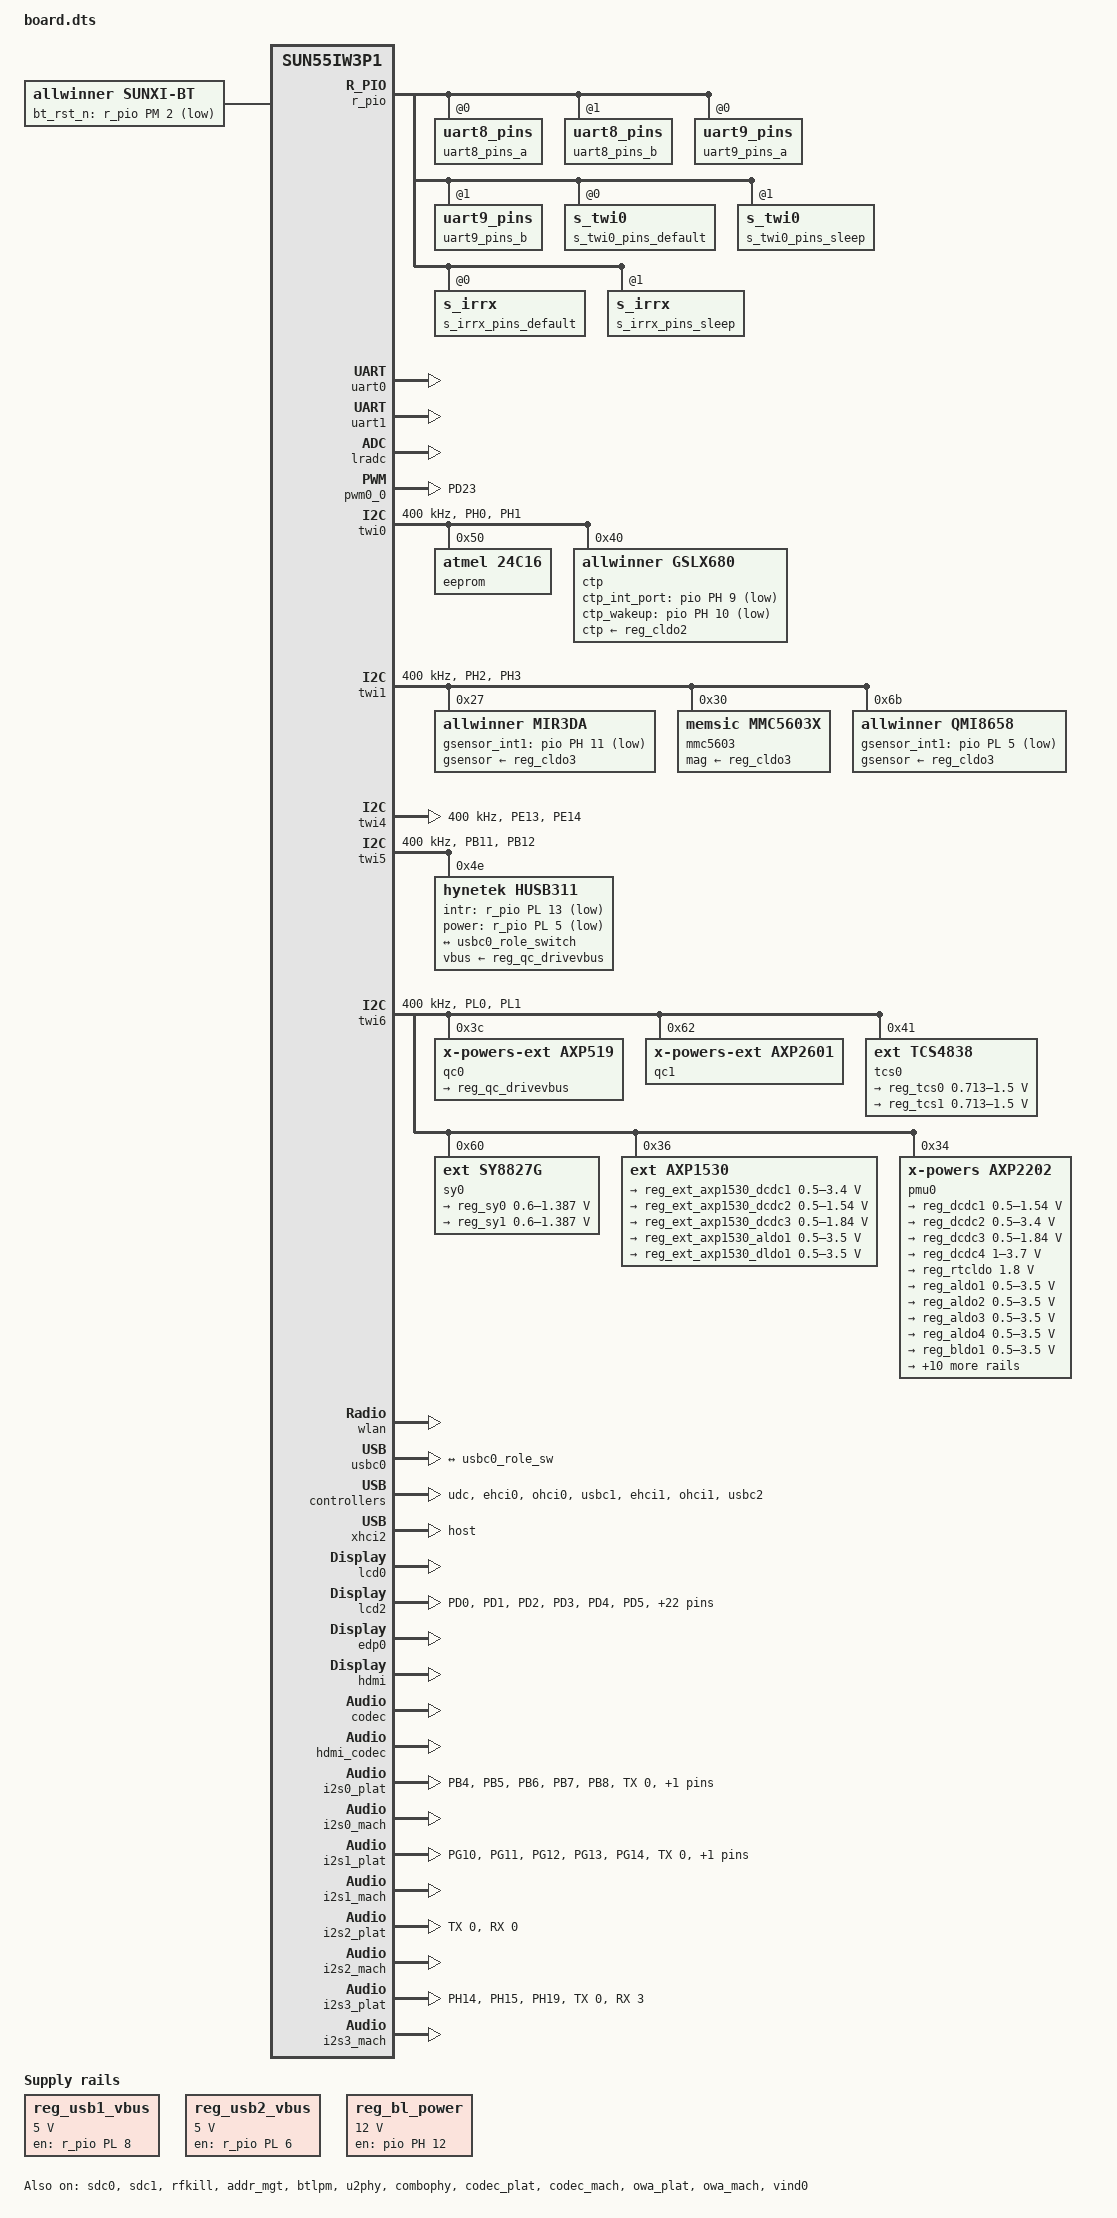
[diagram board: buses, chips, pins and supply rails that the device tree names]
/*
 * Allwinner Technology CO., Ltd.
 */

/dts-v1/;

#include "sun55iw3p1.dtsi"

/{
	board = "A527", "A527-PRO2-AXP717C";
	compatible = "allwinner,a523", "arm,sun55iw3p1";
	aliases {
		pmu0 = &pmu0;
		axp1530 = &axp1530;
		serial0 = &uart0;
		lcd0 = &lcd0;
		hdmi = &hdmi;
		reg-tcs0 = &reg_tcs0;
		reg-sy0 = &reg_sy0;
		reg-axp1530 = &reg_ext_axp1530_dcdc1;
		tcs0 = &tcs0;
		sy0 = &sy0;
		cpu-ext = &cpu4;
		standby-param = &standby_param;
		arisc-config = &arisc_config;
	};

	reg_usb1_vbus: usb1-vbus {
		compatible = "regulator-fixed";
		regulator-name = "usb1-vbus";
		regulator-min-microvolt = <5000000>;
		regulator-max-microvolt = <5000000>;
		regulator-enable-ramp-delay = <1000>;
		gpio = <&r_pio PL 8 GPIO_ACTIVE_HIGH>;
		enable-active-high;
	};

	reg_usb2_vbus: usb2-vbus {
		compatible = "regulator-fixed";
		regulator-name = "usb2-vbus";
		regulator-min-microvolt = <5000000>;
		regulator-max-microvolt = <5000000>;
		regulator-enable-ramp-delay = <1000>;
		gpio = <&r_pio PL 6 GPIO_ACTIVE_HIGH>;
		enable-active-high;
	};

	reg_bl_power: backlight-power {
		compatible = "regulator-fixed";
		regulator-name = "backlight-power";
		regulator-min-microvolt = <12000000>;
		regulator-max-microvolt = <12000000>;
		regulator-enable-ramp-delay = <1000>;
		regulator-boot-on;
		gpio = <&pio PH 12 GPIO_ACTIVE_HIGH>;
		enable-active-high;
	};


	standby_param: standby_param {
		vdd-cpu = <0x00000001>;
		vdd-cpub = <0x00000001>;
		vdd-ndr = <0x00000004>;
		vdd-sys = <0x00000002>;
		vcc-pll = <0x00000080>;
		vcc-io  = <0x00004000>;

		osc24m-on = <0x0>;
	};

	arisc_config: arisc_config {
		s_uart_config{
			pins = "PL2", "PL3";
			function = <2>, <2>;
			status = "disabled";
		};
	};
};

&r_pio {
	uart8_pins_a: uart8_pins@0 {
		pins = "PL2", "PL3";
		function = "s_uart0";
	};

	uart8_pins_b: uart8_pins@1 {
		pins = "PL2", "PL3";
		function = "gpio_in";
	};

	uart9_pins_a: uart9_pins@0 {
		pins = "PM0", "PM1";
		function = "s_uart1";
	};

	uart9_pins_b: uart9_pins@1 {
		pins = "PM0", "PM1";
		function = "gpio_in";
	};

	s_twi0_pins_default: s_twi0@0 {
		pins = "PL0", "PL1";
		function = "s_twi0";
		drive-strength = <10>;
		bias-pull-up;
	};

	s_twi0_pins_sleep: s_twi0@1 {
		pins = "PL0", "PL1";
		function = "gpio_in";
	};

	s_irrx_pins_default: s_irrx@0 {
		pins = "PL11";
		function = "s_cir";
	};

	s_irrx_pins_sleep: s_irrx@1 {
	        pins = "PL11";
		function = "gpio_in";
	};
};

&pio {
	vcc-pg-supply = <&reg_pio1_8>;
	vcc-pc-supply = <&reg_pio1_8>;
	vcc-pf-supply = <&reg_pio1_8>;
	vcc-pfo-supply = <&reg_pio3_3>;

	uart0_pins_a: uart0_pins@0 {
		pins = "", "";
		function = "uart0";
	};

	uart0_pins_b: uart0_pins@1 {
		pins = "", "";
		function = "gpio_in";
	};

	uart2_pins_a: uart2_pins@0 {
		pins = "PB0", "PB1";
		function = "uart2";
	};

	uart2_pins_b: uart2_pins@1 {
		pins = "PB0", "PB1";
		function = "gpio_in";
	};

	uart3_pins_a: uart3_pins@0 {
		pins = "PD14", "PD15";
		function = "uart3";
	};

	uart3_pins_b: uart3_pins@1 {
		pins = "PD14", "PD15";
		function = "gpio_in";
	};

	uart4_pins_a: uart4_pins@0 {
		pins = "PD18", "PD19";
		function = "uart4";
	};

	uart4_pins_b: uart4_pins@1 {
		pins = "PD18", "PD19";
		function = "gpio_in";
	};

	uart5_pins_a: uart5_pins@0 {
		pins = "PE11", "PE12";
		function = "uart5";
	};

	uart5_pins_b: uart5_pins@1 {
		pins = "PE11", "PE12";
		function = "gpio_in";
	};

	uart6_pins_a: uart6_pins@0 {
		pins = "PK18", "PK19";
		function = "uart6";
	};

	uart6_pins_b: uart6_pins@1 {
		pins = "PK18", "PK19";
		function = "gpio_in";
	};

	uart7_pins_a: uart7_pins@0 {
		pins = "PB11", "PB12";
		function = "uart7";
	};

	uart7_pins_b: uart7_pins@1 {
		pins = "PB11", "PB12";
		function = "gpio_in";
	};

	pwm0_0_pin_active: pwm0_0@0 {
		pins = "PD23";
		function = "pwm0_0";
		drive-strength = <10>;
	};

	pwm0_0_pin_sleep: pwm0_0@1 {
		pins = "PD23";
		function = "gpio_in";
	};

	ledc_pins_a: ledc@0 {
		pins = "PE5";
		function = "ledc";
		drive-strength = <10>;
	};

	ledc_pins_b: ledc@1 {
		pins = "PE5";
		function = "gpio_in";
	};

	irrx_pins_default: irrx@0 {
		pins = "PH19";
		function = "cir";
	};

	irrx_pins_sleep: irrx@1 {
	        pins = "PH19";
	        function = "gpio_in";
	};

	irtx_pins_default: irtx@0 {
		pins = "PH18";
		function = "cir";
	};

	irtx_pins_sleep: irtx@1 {
		pins = "PH18";
		function = "gpio_in";
	};

	twi0_pins_default: twi0@0 {
		pins = "PH0", "PH1";
		function = "twi0";
		drive-strength = <10>;
		bias-pull-up;
	};

	twi0_pins_sleep: twi0@1 {
		pins = "PH0", "PH1";
		function = "gpio_in";
	};

	twi1_pins_default: twi1@0 {
		pins = "PH2", "PH3";
		function = "twi1";
		drive-strength = <10>;
		bias-pull-up;
	};

	twi1_pins_sleep: twi1@1 {
		pins = "PH2", "PH3";
		function = "gpio_in";
	};

	twi4_pins_default: twi4@0 {
		pins = "PE13", "PE14";
		function = "twi4";
		drive-strength = <20>;
		bias-pull-up;
	};

	twi4_pins_sleep: twi4@1 {
		pins = "PE13", "PE14";
		function = "gpio_in";
	};

	twi5_pins_default: twi5@0 {
		pins = "PB11", "PB12";
		function = "twi5";
		drive-strength = <30>;
		bias-pull-up;
	};

	twi5_pins_sleep: twi5@1 {
		pins = "PB11", "PB12";
		function = "gpio_in";
	};

	rgb24_pins_a: rgb24@0 {
		pins = "PD0", "PD1", "PD2", "PD3", "PD4", "PD5", "PD6", "PD7", "PD8", "PD9", \
			"PD10", "PD11", "PD12", "PD13", "PD14", "PD15", "PD16", "PD17", "PD18", "PD19", \
			"PD20", "PD21", "PD22","PD23","PD24","PD25","PD26","PD27";
		      function = "dpss";
		      drive-strength = <30>;
	      };
	rgb24_pins_b: rgb24@1 {
		pins = "PD0", "PD1", "PD2", "PD3", "PD4", "PD5", "PD6", "PD7", "PD8", "PD9", \
			"PD10", "PD11", "PD12", "PD13", "PD14", "PD15", "PD16", "PD17", "PD18", "PD19", \
			"PD20", "PD21", "PD22", "PD23","PD24","PD25","PD26","PD27";
		      function = "gpio_in";
	      };
	lvds0_pins_a: lvds0@0 {
		pins = "PD0", "PD1", "PD2", "PD3", "PD4", "PD5", "PD6", "PD7", "PD8", "PD9";
		      function = "lvds";
		      drive-strength = <30>;
	      };
	lvds0_pins_b: lvds0@1 {
		      pins = "PD0", "PD1", "PD2", "PD3", "PD4", "PD5", "PD6", "PD7", "PD8", "PD9";
		      function = "gpio_in";
	      };

	csi_mclk3_pins_a: csi_mclk3@0 {
		pins = "PE10";
		function = "mipi3";
		drive-strength = <20>;
	};

	csi_mclk3_pins_b: csi_mclk3@1 {
		pins = "PE10";
		function = "gpio_in";
	};

	ncsi_pins_a: ncsi@0 {
		pins = "PK12", "PK14", "PK15",
		"PK16", "PK17", "PK18", "PK19",
		"PK20", "PK21", "PK22", "PK23",
		"PE6", "PE7", "PE8", "PE9",
		"PE10", "PE11", "PE12", "PE15";
		function = "ncsi";
		drive-strength = <20>;
	};

	ncsi_pins_b: ncsi@1 {
		pins = "PK12", "PK14", "PK15",
		"PK16", "PK17", "PK18", "PK19",
		"PK20", "PK21", "PK22", "PK23",
		"PE6", "PE7", "PE8", "PE9",
		"PE10", "PE11", "PE12", "PE15";
		function = "gpio_in";
	};

	i2s1_pins_a: i2s1@0 {
		pins = "PG10", "PG11", "PG12";
		function = "i2s1";
		drive-strength = <20>;
		bias-disable;
	};

	i2s1_pins_b: i2s1@1 {
		pins = "PG10", "PG11", "PG12", "PG13", "PG14";
		function = "io_disabled";
		drive-strength = <20>;
		bias-disable;
	};

	i2s1_pins_c: i2s1@2 {
		pins = "PG13";
		function = "i2s1_dout";
		drive-strength = <20>;
		bias-disable;
	};

	i2s1_pins_d: i2s1@3 {
		pins = "PG14";
		function = "i2s1_din";
		drive-strength = <20>;
		bias-disable;
	};

	i2s3_pins_a: i2s3@0 {
		pins = "PH14", "PH15";
		function = "i2s3";
		drive-strength = <20>;
		bias-disable;
	};

	i2s3_pins_b: i2s3@1 {
		pins = "PH14", "PH15", "PH19";
		function = "io_disabled";
		drive-strength = <20>;
		bias-disable;
	};

	i2s3_pins_c: i2s3@2 {
		pins = "PH19";
		function = "i2s3_din";
		drive-strength = <20>;
		bias-disable;
	};

	owa_pins_a: owa@0 {
		pins = "PH7";
		function = "owa";
		drive-strength = <20>;
		bias-disable;
	};

	owa_pins_b: owa@1 {
		pins = "PH7";
		function = "io_disabled";
		drive-strength = <20>;
		bias-disable;
	};

	nand0_pins_default: nand0@0 {
		pins = "PC0", "PC1", "PC2", "PC5",
			 "PC8", "PC9", "PC10", "PC11",
			 "PC12", "PC13", "PC14", "PC15",
			 "PC16";
		function = "nand0";
		drive-strength = <30>;
	};

	nand0_pins_rb: nand0@1 {
		pins = "PC4", "PC6", "PC3", "PC7";
		function = "nand0";
		drive-strength = <30>;
		bias-pull-up;   /* only RB&CE should be pulled up */
	};

	nand0_pins_sleep: nand0@2 {
		pins = "PC0", "PC1", "PC2", "PC3",
			 "PC4", "PC5", "PC6", "PC7",
			 "PC8", "PC9", "PC10", "PC11",
			 "PC12", "PC13", "PC14", "PC15",
			 "PC16";
		function = "io_disabled";
		drive-strength = <10>;
	};

	i2s0_pins_a: i2s0@0 {
		pins = "PB4", "PB5", "PB6";
		function = "i2s0";
		drive-strength = <20>;
		bias-disable;
	};

	i2s0_pins_b: i2s0@1 {
		pins = "PB4", "PB5", "PB6", "PB7", "PB8";
		function = "io_disabled";
		drive-strength = <20>;
		bias-disable;
	};

	i2s0_pins_c: i2s0@2 {
		pins = "PB7";
		function = "i2s0_dout";
		drive-strength = <20>;
		bias-disable;
	};

	i2s0_pins_d: i2s0@3 {
		pins = "PB8";
		function = "i2s0_din";
		drive-strength = <20>;
		bias-disable;
	};
};

&soc {
	auto_print@54321 {
		reg = <0x0 0x54321 0x0 0x0>;
		device_type = "auto_print";
		status = "okay";
	};

	hall_para {
		hall_name = "MH248";
		status = "okay";
		hall_int_port = <&r_pio PL 9 GPIO_ACTIVE_LOW>;
	};

};

&uart0 {
	pinctrl-names = "default", "sleep";
	pinctrl-0 = <&uart0_pins_a>;
	pinctrl-1 = <&uart0_pins_b>;
	uart-supply = <&reg_cldo3>;
	status = "okay";
};

&uart1 {
	status = "okay";
};

&uart2 {
	pinctrl-names = "default", "sleep";
	pinctrl-0 = <&uart2_pins_a>;
	pinctrl-1 = <&uart2_pins_b>;
	status = "disabled";
};

&uart3 {
	pinctrl-names = "default", "sleep";
	pinctrl-0 = <&uart3_pins_a>;
	pinctrl-1 = <&uart3_pins_b>;
	status = "disabled";
};

&uart4 {
	pinctrl-names = "default", "sleep";
	pinctrl-0 = <&uart4_pins_a>;
	pinctrl-1 = <&uart4_pins_b>;
	status = "disabled";
};

&uart5 {
	pinctrl-names = "default", "sleep";
	pinctrl-0 = <&uart5_pins_a>;
	pinctrl-1 = <&uart5_pins_b>;
	status = "disabled";
};

&uart6 {
	pinctrl-names = "default", "sleep";
	pinctrl-0 = <&uart6_pins_a>;
	pinctrl-1 = <&uart6_pins_b>;
	status = "disabled";
};

&uart7 {
	pinctrl-names = "default", "sleep";
	pinctrl-0 = <&uart7_pins_a>;
	pinctrl-1 = <&uart7_pins_b>;
	status = "disabled";
};

&uart8 {
	pinctrl-names = "default", "sleep";
	pinctrl-0 = <&uart8_pins_a>;
	pinctrl-1 = <&uart8_pins_b>;
	status = "disabled";
};

&uart9 {
	pinctrl-names = "default", "sleep";
	pinctrl-0 = <&uart9_pins_a>;
	pinctrl-1 = <&uart9_pins_b>;
	status = "disabled";
};

&lradc {
	key_cnt = <2>;
	key0 = <646 115>;
	key1 = <900 114>;
	status = "okay";
};

&gpadc0 {
	channel_num = <2>;
	channel_select = <3>;
	channel_data_select = <3>;
	channel_compare_select = <3>;
	channel_cld_select = <3>;
	channel_chd_select = <3>;
	channel0_compare_lowdata = <1700000>;
	channel0_compare_higdata = <1200000>;
	channel1_compare_lowdata = <460000>;
	channel1_compare_higdata = <1200000>;
	status = "disabled";
};

&gpadc1 {
	channel_num = <2>;
	channel_select = <3>;
	channel_data_select = <3>;
	channel_compare_select = <3>;
	channel_cld_select = <3>;
	channel_chd_select = <3>;
	channel0_compare_lowdata = <1700000>;
	channel0_compare_higdata = <1200000>;
	channel1_compare_lowdata = <460000>;
	channel1_compare_higdata = <1200000>;
	status = "disabled";
};

&pwm0_0 {
	pinctrl-names = "active", "sleep";
	pinctrl-0 = <&pwm0_0_pin_active>;
	pinctrl-1 = <&pwm0_0_pin_sleep>;
	status = "okay";
};

&ledc  {
	pinctrl-names = "default", "sleep";
	pinctrl-0 = <&ledc_pins_a>;
	pinctrl-1 = <&ledc_pins_b>;
	led_count = <34>;
	output_mode = "GRB";
	reset_ns = <84>;
	t1h_ns = <800>;
	t1l_ns = <320>;
	t0h_ns = <300>;
	t0l_ns = <800>;
	wait_time0_ns = <84>;
	wait_time1_ns = <84>;
	wait_data_time_ns = <600000>;
	status = "disabled";
};

&irrx {
	pinctrl-names = "default", "sleep";
	pinctrl-0 = <&irrx_pins_default>;
	pinctrl-1 = <&irrx_pins_sleep>;
	status = "disabled";
};

&s_irrx {
	pinctrl-names = "default", "sleep";
	pinctrl-0 = <&s_irrx_pins_default>;
	pinctrl-1 = <&s_irrx_pins_sleep>;
	status = "disabled";
};

&irtx {
	pinctrl-names = "default", "sleep";
	pinctrl-0 = <&irtx_pins_default>;
	pinctrl-1 = <&irtx_pins_sleep>;
	status = "disabled";
};

&twi0 {
	clock-frequency = <400000>;
	pinctrl-0 = <&twi0_pins_default>;
	pinctrl-1 = <&twi0_pins_sleep>;
	pinctrl-names = "default", "sleep";
	/* For stability and backwards compatibility, we recommend setting ‘twi_drv_used’ to 1 */
	twi_drv_used = <1>;
	status = "okay";

	eeprom@50 {
		compatible = "atmel,24c16";
		reg = <0x50>;
		status = "okay";
	};
	pcie_usb_phy@74 {
		compatible = "combphy,phy74";
		reg = <0x74>;
		status = "disabled";
	};
	pcie_usb_phy@75 {
		compatible = "combphy,phy75";
		reg = <0x75>;
		status = "disabled";
	};

	ctp: ctp@0 {
		compatible = "allwinner,gslX680";
		reg = <0x40>;
		device_type = "ctp";
		status = "okay";
		ctp_name = "gslX680_5680_d10";
		ctp_twi_id = <0x0>;
		ctp_twi_addr = <0x40>;
		ctp_screen_max_x = <0x780>;
		ctp_screen_max_y = <0x438>;
		ctp_revert_x_flag = <0x0>;
		ctp_revert_y_flag = <0x0>;
		ctp_exchange_x_y_flag = <0x1>;
		ctp_int_port = <&pio PH 9 GPIO_ACTIVE_LOW>;
		//ctp_power_io = <&pio PH 14 GPIO_ACTIVE_LOW>;
		ctp_wakeup = <&pio PH 10 GPIO_ACTIVE_LOW>;
		ctp-supply = <&reg_cldo2>;
		ctp_power_ldo_vol = <3300>;
	};
};

&twi1 {
	clock-frequency = <400000>;
	pinctrl-0 = <&twi1_pins_default>;
	pinctrl-1 = <&twi1_pins_sleep>;
	pinctrl-names = "default", "sleep";
	/* For stability and backwards compatibility, we recommend setting ‘twi_drv_used’ to 1 */
	twi_drv_used = <1>;
	status = "okay";
        /*DA215S  DA221*/
	mir3da {
		compatible = "allwinner,mir3da";
		reg = <0x27>;
		device_type = "gsensor";
		status = "okay";
		gsensor_twi_id = <0x1>;
		gsensor_twi_addr = <0x27>;
		gsensor_int1 = <&pio PH 11 (GPIO_ACTIVE_LOW | GPIO_PULL_UP)>;
		gsensor-supply = <&reg_cldo3>;
		gsensor_vcc_io_val = <3300>;
	};
	/*ms311*/
	msa {
		compatible = "allwinner,msa";
		reg = <0x62>;
		device_type = "gsensor";
		status = "disabled";
		gsensor_twi_id = <0x1>;
		gsensor_twi_addr = <0x62>;
		gsensor_int1 = <&pio PH 11 (GPIO_ACTIVE_LOW | GPIO_PULL_UP)>;
		gsensor-supply = <&reg_cldo3>;
		gsensor_vcc_io_val = <3300>;
	};
	mmc5603 {
		compatible = "memsic,mmc5603x";
		reg = <0x30>;
		status = "okay";
		device_type = "magnetormetersensor";
		mag_twi_id = <0x1>;
		mag_twi_addr = <0x26>;
		mag-supply = <&reg_cldo3>;
		mag_vcc_io_val = <3300>;
	};

	qmi8658 {
		compatible = "allwinner,qmi8658";
		reg = <0x6b>;
		device_type = "gsensor";
		status = "okay";
		gsensor_twi_id = <0x1>;
		gsensor_twi_addr = <0x6b>;
		gsensor_int1 = <&pio PL 5 (GPIO_ACTIVE_LOW | GPIO_PULL_UP)>;
		gsensor-supply = <&reg_cldo3>;
		gsensor_vcc_io_val = <3300>;
	};
};

&twi4 {
	clock-frequency = <400000>;
	pinctrl-0 = <&twi4_pins_default>;
	pinctrl-1 = <&twi4_pins_sleep>;
	pinctrl-names = "default", "sleep";
	/* For stability and backwards compatibility, we recommend setting ‘twi_drv_used’ to 1 */
	twi_drv_used = <1>;
	status = "okay";
};

&twi5 {
	clock-frequency = <400000>;
	pinctrl-0 = <&twi5_pins_default>;
	pinctrl-1 = <&twi5_pins_sleep>;
	pinctrl-names = "default", "sleep";
	/* For stability and backwards compatibility, we recommend setting ‘twi_drv_used’ to 1 */
	twi_drv_used = <1>;
	status = "okay";

	ac107: ac107@36 {
		#sound-dai-cells        = <0>;
		compatible              = "allwinner,sunxi-ac107";
		reg                     = <0x36>;
		pllclk-src              = "MCLK";
		sysclk-src              = "MCLK";
		pcm-bit-first           = "MSB";
		frame-sync-width        = <1>;
		rx-chmap                = <0xaaaa>;
		ch1-dig-vol             = <160>;
		ch2-dig-vol             = <160>;
		ch1-pga-gain            = <26>;
		ch2-pga-gain            = <26>;
		status                  = "disabled";
	};
	husb311: husb311@4e {
		compatible = "hynetek,husb311";
		reg = <0x4e>;
		interrupt-parent = <&r_pio>;
		husb311,intr_gpio = <&r_pio PL 13 GPIO_ACTIVE_LOW>;
		power_gpios = <&r_pio PL 5 GPIO_ACTIVE_LOW>;
		vbus-supply = <&reg_qc_drivevbus>;
		det_usb_supply = <&charger_power_supply>;
		aw,vbus-debounce-quirk;
		aw,vbus-tryon-debounce = <1200>;
		aw,vbus-check-debounce = <600>;
		/* aw,vbus-wakeup-quirk; */
		/* aw,port-reset-quirk; */
		aw,otg-detect-quirk;
		status = "okay";

		ports {
			#address-cells = <1>;
			#size-cells = <0>;

			port@0 {
				reg = <0>;
				usbc0_role_sw: endpoint@0 {
					remote-endpoint = <&usbc0_role_switch>;
				};
			};
		};

		usb_con: connector {
			compatible = "usb-c-connector";
			label = "USB-C";
			data-role = "dual";
			power-role = "dual";
			try-power-role = "sink";
			op-sink-microwatt = <1000000>;
			slow-charger-loop;
			//pd-disable;
			//typec-power-opmode = "default";
			sink-pdos = < PDO_FIXED(5000, 500, (0x1<<29)|(0x1<<25))
						 PDO_VAR(5000, 5000, 2000)
						 PDO_VAR(9000, 9000, 2000)
						 PDO_VAR(12000, 12000, 3000)
						 PDO_VAR(15000, 15000, 3000)
						 PDO_VAR(20000, 20000, 2250)
						>;
			source-pdos = < PDO_FIXED(5000, 500, (0x1<<29)|(0x1<<25))
							PDO_VAR(5000, 5000, 1200) >;
			/* fixme */
			sink-vdos = <0xd1002e99 0x00 0x03110000>;
			sink-vdos-v1 = <0xd1002e99 0x00 0x03110000>;

			altmodes {
				#address-cells = <1>;
				#size-cells = <0>;

				altmode@0 {
					reg = <0>;
					svid = <0xff01>;
					vdo = <0xffffffff>;
				};
			};

			ports {
				#address-cells = <1>;
				#size-cells = <0>;

/*
				port@0 {
					reg = <0>;
					usbc2_orien_sw: endpoint {
						remote-endpoint = <&usbdp_orientation_switch>;
					};
				};
				port@1 {
					reg = <1>;
					dp_altmode_mux: endpoint {
						remote-endpoint = <&usbdp_dp_altmode_mux>;
					};
				};
*/
			};
		};
	};
};
&twi6 {
	clock-frequency = <400000>;
	pinctrl-0 = <&s_twi0_pins_default>;
	pinctrl-1 = <&s_twi0_pins_sleep>;
	pinctrl-names = "default", "sleep";
	device_type = "twi6";
	/* For stability and backwards compatibility, we recommend setting ‘twi_drv_used’ to 1 */
	twi_drv_used = <1>;
	no_suspend = <1>;
	status = "okay";

	qc0: qc@3c{
		compatible = "x-powers-ext,axp519";
		reg = <0x3c>;
		status = "okay";
		interrupts = <0 IRQ_TYPE_LEVEL_LOW>;
		interrupt-parent = <&nmi_intc>;
		quick-charge,drive-vbus-en;
		wakeup-source;

		charger_power_supply: charger_power_supply{
			compatible = "x-powers-ext,axp519-charger-power-supply";
			status = "okay";
			wakeup-source;
			det_battery_supply = <&qc_bat_power_supply>;
			pmu_runtime_chgcur = <2000>;
			pmu_suspend_chgcur = <3000>;
			pmu_shutdown_chgcur = <3000>;
			pmu_chargerpc_vol = <5000>;
			pmu_chargerpc_cur = <500>;
			pmu_chargerad_vol = <5000>;
			pmu_chargerad_cur = <2400>;
			battery_exist_sets = <1>;
		};
		regulator4: regulators@4 {
			reg_qc_drivevbus: drivevbus {
				regulator-name = "axp519-drivevbus";
				regulator-enable-ramp-delay = <1000>;
			};
		};
	};

	qc1: qc@62{
		compatible = "x-powers-ext,axp2601";
		reg = <0x62>;
		status = "okay";
		interrupts = <0 IRQ_TYPE_LEVEL_LOW>;
		interrupt-parent = <&nmi_intc>;
		wakeup-source;

		qc_bat_power_supply: qc_bat_power_supply {
			compatible = "x-powers-ext,axp2601-bat-power-supply";
			param = <&axp2202_parameter>;
			status = "okay";
			wakeup-source;
			det_qc_supply = <&charger_power_supply>;
			pmu_init_chgvol = <8700>;

			pmu_bat_temp_enable = <1>;
			pmu_bat_charge_ltf = <27280>;//0
			pmu_bat_charge_htf = <3536>;//55
			pmu_bat_work_ltf = <27280>;//0
			pmu_bat_work_htf = <3536>;//55
			pmu_bat_shutdown_ltf = <42470>;//-10
			pmu_bat_shutdown_htf = <2588>;//65
			pmu_bat_temp_para1 = <86430>;//-25
			pmu_bat_temp_para2 = <53410>;//-15
			pmu_bat_temp_para3 = <42470>;//-10
			pmu_bat_temp_para4 = <33900>;//-5
			pmu_bat_temp_para5 = <27280>;//0
			pmu_bat_temp_para6 = <22050>;//5
			pmu_bat_temp_para7 = <17960>;//10
			pmu_bat_temp_para8 = <14690>;//15
			pmu_bat_temp_para9 = <12090>;//20
			pmu_bat_temp_para10 = <10000>;//25
			pmu_bat_temp_para11 = <8313>;//30
			pmu_bat_temp_para12 = <5827>;//40
			pmu_bat_temp_para13 = <4911>;//45
			pmu_bat_temp_para14 = <4160>;//50
			pmu_bat_temp_para15 = <3536>;//55
			pmu_bat_temp_para16 = <2588>;//65

			wakeup_new_soc;
		};
	};

	tcs0: tcs@41 {
		compatible = "ext,tcs4838";
		reg = <0x41>;
		status = "okay";
		tcs4838_delay = <0>;
		regulator1: regulators@1 {
			reg_tcs0: dcdc0 {
				regulator-name = "tcs4838-dcdc0";
				regulator-min-microvolt = <712500>;
				regulator-max-microvolt = <1500000>;
				regulator-ramp-delay = <520>;
				regulator-enable-ramp-delay = <1000>;
				regulator-always-on;
				regulator-boot-on;
			};
			reg_tcs1: dcdc1 {
				regulator-name = "tcs4838-dcdc1";
				regulator-min-microvolt = <712500>;
				regulator-max-microvolt = <1500000>;
				regulator-ramp-delay = <520>;
				regulator-enable-ramp-delay = <1000>;
			};
		};
		virtual-ext-dcdc0 {
			compatible = "xpower-vregulator,ext-dcdc0";
			dcdc0-supply = <&reg_tcs0>;
		};
		virtual-ext-dcdc1 {
			compatible = "xpower-vregulator,ext-dcdc1";
			dcdc1-supply = <&reg_tcs1>;
		};
	};

	sy0: sy@60 {
		compatible = "ext,sy8827g";
		reg = <0x60>;
		status = "okay";
		sy8827g_delay = <0>;
		regulator2: regulators@2 {
			reg_sy0: dcdc0 {
				regulator-name = "sy8827g-dcdc0";
				regulator-min-microvolt = <600000>;
				regulator-max-microvolt = <1387500>;
				regulator-ramp-delay = <520>;
				regulator-enable-ramp-delay = <1000>;
				regulator-always-on;
				regulator-boot-on;
			};
			reg_sy1: dcdc1 {
				regulator-name = "sy8827g-dcdc1";
				regulator-min-microvolt = <600000>;
				regulator-max-microvolt = <1387500>;
				regulator-ramp-delay = <520>;
				regulator-enable-ramp-delay = <1000>;
			};
		};
		virtual-ext-dcdc0 {
			compatible = "xpower-vregulator,ext-dcdc0";
			dcdc0-supply = <&reg_sy0>;
		};
		virtual-ext-dcdc1 {
			compatible = "xpower-vregulator,ext-dcdc1";
			dcdc1-supply = <&reg_sy1>;
		};
	};

	axp1530: axp1530@36{
		compatible = "ext,axp1530";
		status = "okay";
		reg = <0x36>;

		wakeup-source;

		regulators{
			reg_ext_axp1530_dcdc1: dcdc1 {
				regulator-name = "axp1530-dcdc1";
				regulator-min-microvolt = <500000>;
				regulator-max-microvolt = <3400000>;
				regulator-step-delay-us = <25>;
				regulator-final-delay-us = <50>;
				regulator-always-on;
			};

			reg_ext_axp1530_dcdc2: dcdc2 {
				regulator-name = "axp1530-dcdc2";
				regulator-min-microvolt = <500000>;
				regulator-max-microvolt = <1540000>;
				regulator-step-delay-us = <25>;
				regulator-final-delay-us = <50>;
				regulator-ramp-delay = <200>; /* FIXME */
				regulator-always-on;
			};

			reg_ext_axp1530_dcdc3: dcdc3 {
				regulator-name = "axp1530-dcdc3";
				regulator-min-microvolt = <500000>;
				regulator-max-microvolt = <1840000>;
				regulator-step-delay-us = <25>;
				regulator-final-delay-us = <50>;
				regulator-always-on;
			};

			reg_ext_axp1530_aldo1: ldo1 {
				regulator-name = "axp1530-aldo1";
				regulator-min-microvolt = <500000>;
				regulator-max-microvolt = <3500000>;
				regulator-step-delay-us = <25>;
				regulator-final-delay-us = <50>;
			};

			reg_ext_axp1530_dldo1: ldo2 {
				regulator-name = "axp1530-dldo1";
				regulator-min-microvolt = <500000>;
				regulator-max-microvolt = <3500000>;
				regulator-step-delay-us = <25>;
				regulator-final-delay-us = <50>;
			};
		};
		virtual-ext-dcdc1 {
			compatible = "xpower-vregulator,ext-dcdc1";
			dcdc1-supply = <&reg_ext_axp1530_dcdc1>;
		};
		virtual-ext-dcdc2 {
			compatible = "xpower-vregulator,ext-dcdc2";
			dcdc2-supply = <&reg_ext_axp1530_dcdc2>;
		};
		virtual-ext-dcdc3 {
			compatible = "xpower-vregulator,ext-dcdc3";
			dcdc3-supply = <&reg_ext_axp1530_dcdc3>;
		};
		virtual-ext-aldo1 {
			compatible = "xpower-vregulator,ext-aldo1";
			aldo1-supply = <&reg_ext_axp1530_aldo1>;
		};
		virtual-ext-dldo1 {
			compatible = "xpower-vregulator,ext-dldo1";
			dldo1-supply = <&reg_ext_axp1530_dldo1>;
		};

	};
	pmu0: pmu@34 {
		compatible = "x-powers,axp2202";
		reg = <0x34>;
		status = "okay";
		interrupts = <0 IRQ_TYPE_LEVEL_LOW>;
		interrupt-parent = <&nmi_intc>;
		x-powers,drive-vbus-en;
		pmu_reset = <0>;
		pmu_irq_wakeup = <1>;
		pmu_hot_shutdown = <1>;

		wakeup-source;

		usb_power_supply: usb_power_supply {
			compatible = "x-powers,axp2202-usb-power-supply";
			status = "disabled";

			pmu_usbpc_vol = <4600>;
			pmu_usbpc_cur = <500>;
			pmu_usbad_vol = <4000>;
			pmu_usbad_cur = <2500>;
			pmu_usb_typec_used = <1>;
			wakeup_usb_in;
			wakeup_usb_out;

			det_acin_supply = <&gpio_power_supply>;
			pmu_acin_usbid_drv = <&pio PH 12 GPIO_ACTIVE_LOW>;
			pmu_vbus_det_gpio = <&pio PH 13 GPIO_ACTIVE_LOW>;
		};

		gpio_power_supply: gpio_power_supply {
			compatible = "x-powers,gpio-supply";
			status = "disabled";
			pmu_acin_det_gpio = <&pio PH 14 GPIO_ACTIVE_LOW>;
			det_usb_supply = <&usb_power_supply>;
		};

		bat_power_supply: bat-power-supply {
			compatible = "x-powers,axp2202-bat-power-supply";
			param = <&axp2202_parameter>;
			status = "disabled";

			pmu_chg_ic_temp = <0>;

			pmu_battery_rdc= <170>;
			pmu_battery_cap = <5000>;
			pmu_runtime_chgcur = <1000>;
			pmu_suspend_chgcur = <1500>;
			pmu_shutdown_chgcur = <1500>;
			pmu_init_chgvol = <4350>;
			pmu_battery_warning_level1 = <15>;
			pmu_battery_warning_level2 = <0>;
			pmu_chgled_func = <0>;
			pmu_chgled_type = <0>;
			pmu_bat_para1 = <0>;
			pmu_bat_para2 = <0>;
			pmu_bat_para3 = <0>;
			pmu_bat_para4 = <0>;
			pmu_bat_para5 = <0>;
			pmu_bat_para6 = <0>;
			pmu_bat_para7 = <2>;
			pmu_bat_para8 = <3>;
			pmu_bat_para9 = <4>;
			pmu_bat_para10 = <6>;
			pmu_bat_para11 = <9>;
			pmu_bat_para12 = <14>;
			pmu_bat_para13 = <26>;
			pmu_bat_para14 = <38>;
			pmu_bat_para15 = <49>;
			pmu_bat_para16 = <52>;
			pmu_bat_para17 = <56>;
			pmu_bat_para18 = <60>;
			pmu_bat_para19 = <64>;
			pmu_bat_para20 = <70>;
			pmu_bat_para21 = <77>;
			pmu_bat_para22 = <83>;
			pmu_bat_para23 = <87>;
			pmu_bat_para24 = <90>;
			pmu_bat_para25 = <95>;
			pmu_bat_para26 = <99>;
			pmu_bat_para27 = <99>;
			pmu_bat_para28 = <100>;
			pmu_bat_para29 = <100>;
			pmu_bat_para30 = <100>;
			pmu_bat_para31 = <100>;
			pmu_bat_para32 = <100>;

			pmu_bat_temp_enable = <1>;
			pmu_jetia_en        = <1>;
			pmu_bat_charge_ltf = <1695>; //-5
			pmu_bat_charge_htf = <151>; //60
			pmu_bat_shutdown_ltf = <2125>; //-10
			pmu_bat_shutdown_htf = <131>; //65
			pmu_jetia_cool = <1361>; //0
			pmu_jetia_warm = <208>; //50
			pmu_jcool_ifall = <0>;//100%
			pmu_jwarm_ifall = <0>;//100%
			pmu_bat_temp_para1 = <4378>; //Murata -25
			pmu_bat_temp_para2 = <2682>; //-15
			pmu_bat_temp_para3 = <2125>; //-10
			pmu_bat_temp_para4 = <1695>; //-5
			pmu_bat_temp_para5 = <1361>;//0
			pmu_bat_temp_para6 = <1101>; //5
			pmu_bat_temp_para7 = <896>; //10
			pmu_bat_temp_para8 = <604>; //20
			pmu_bat_temp_para9 = <416>; //30
			pmu_bat_temp_para10 = <292>; //40
			pmu_bat_temp_para11 = <246>; //45
			pmu_bat_temp_para12 = <208>; //50
			pmu_bat_temp_para13 = <177>; //55
			pmu_bat_temp_para14 = <151>; //60
			pmu_bat_temp_para15 = <111>; //70
			pmu_bat_temp_para16 = <83>; //80

			wakeup_bat_out;
			wakeup_new_soc;
			/* wakeup_bat_in; */
			/* wakeup_bat_charging; */
			/* wakeup_bat_charge_over; */
			/* wakeup_low_warning1; */
			/* wakeup_low_warning2; */
			wakeup_bat_untemp_work;
			wakeup_bat_ovtemp_work;
			/* wakeup_bat_untemp_chg; */
			/* wakeup_bat_ovtemp_chg; */
		};

		powerkey0: powerkey@0 {
			status = "okay";
			compatible = "x-powers,axp2101-pek";
			pmu_powkey_off_time = <6000>;
			pmu_powkey_off_func = <0>;
			pmu_powkey_off_en = <1>;
			pmu_powkey_long_time = <1500>;
			pmu_powkey_on_time = <512>;
			wakeup_rising;
			wakeup_falling;
		};

		regulator0: regulators@0 {
			reg_dcdc1: dcdc1 {
				regulator-name = "axp2202-dcdc1";
				regulator-min-microvolt = <500000>;
				regulator-max-microvolt = <1540000>;
				regulator-ramp-delay = <250>;
				regulator-enable-ramp-delay = <1000>;
				regulator-boot-on;
				regulator-always-on;
			};
			reg_dcdc2: dcdc2 {
				regulator-name = "axp2202-dcdc2";
				regulator-min-microvolt = <500000>;
				regulator-max-microvolt = <3400000>;
				regulator-ramp-delay = <250>;
				regulator-enable-ramp-delay = <1000>;
				regulator-boot-on;
				regulator-always-on;
			};
			reg_dcdc3: dcdc3 {
				regulator-name = "axp2202-dcdc3";
				regulator-min-microvolt = <500000>;
				regulator-max-microvolt = <1840000>;
				regulator-ramp-delay = <250>;
				regulator-enable-ramp-delay = <1000>;
				regulator-always-on;
			};
			reg_dcdc4: dcdc4 {
				regulator-name = "axp2202-dcdc4";
				regulator-min-microvolt = <1000000>;
				regulator-max-microvolt = <3700000>;
				regulator-ramp-delay = <250>;
				regulator-enable-ramp-delay = <1000>;
			};
			reg_rtcldo: rtcldo {
				/* RTC_LDO is a fixed, always-on regulator */
				regulator-name = "axp2202-rtcldo";
				regulator-min-microvolt = <1800000>;
				regulator-max-microvolt = <1800000>;
				regulator-boot-on;
				regulator-always-on;
			};
			reg_aldo1: aldo1 {
				regulator-name = "axp2202-aldo1";
				regulator-min-microvolt = <500000>;
				regulator-max-microvolt = <3500000>;
				regulator-enable-ramp-delay = <1000>;
			};
			reg_aldo2: aldo2 {
				regulator-name = "axp2202-aldo2";
				regulator-min-microvolt = <500000>;
				regulator-max-microvolt = <3500000>;
				regulator-enable-ramp-delay = <1000>;
			};
			reg_aldo3: aldo3 {
				regulator-name = "axp2202-aldo3";
				regulator-min-microvolt = <500000>;
				regulator-max-microvolt = <3500000>;
				regulator-enable-ramp-delay = <1000>;
				regulator-always-on;
				regulator-boot-on;
			};
			reg_aldo4: aldo4 {
				regulator-name = "axp2202-aldo4";
				regulator-min-microvolt = <500000>;
				regulator-max-microvolt = <3500000>;
				regulator-enable-ramp-delay = <1000>;
				regulator-always-on;
				regulator-boot-on;
			};
			reg_bldo1: bldo1 {
				regulator-name = "axp2202-bldo1";
				regulator-min-microvolt = <500000>;
				regulator-max-microvolt = <3500000>;
				regulator-enable-ramp-delay = <1000>;
			};
			reg_bldo2: bldo2 {
				regulator-name = "axp2202-bldo2";
				regulator-min-microvolt = <500000>;
				regulator-max-microvolt = <3500000>;
				regulator-enable-ramp-delay = <1000>;
				regulator-boot-on;
				regulator-always-on;
			};
			reg_bldo3: bldo3 {
				regulator-name = "axp2202-bldo3";
				regulator-min-microvolt = <500000>;
				regulator-max-microvolt = <3500000>;
				regulator-enable-ramp-delay = <1000>;
			};
			reg_bldo4: bldo4 {
				regulator-name = "axp2202-bldo4";
				regulator-min-microvolt = <500000>;
				regulator-max-microvolt = <3500000>;
				regulator-enable-ramp-delay = <1000>;
			};
			reg_cldo1: cldo1 {
				regulator-name = "axp2202-cldo1";
				regulator-min-microvolt = <500000>;
				regulator-max-microvolt = <3500000>;
				regulator-enable-ramp-delay = <1000>;
			};
			reg_cldo2: cldo2 {
				regulator-name = "axp2202-cldo2";
				regulator-min-microvolt = <500000>;
				regulator-max-microvolt = <3500000>;
				regulator-enable-ramp-delay = <1000>;
			};
			reg_cldo3: cldo3 {
				regulator-name = "axp2202-cldo3";
				regulator-min-microvolt = <500000>;
				regulator-max-microvolt = <3500000>;
				regulator-ramp-delay = <2500>;
				regulator-enable-ramp-delay = <1000>;
				regulator-boot-on;
				regulator-always-on;
			};
			reg_cldo4: cldo4 {
				regulator-name = "axp2202-cldo4";
				regulator-min-microvolt = <500000>;
				regulator-max-microvolt = <3500000>;
				regulator-enable-ramp-delay = <1000>;
			};
			reg_cpusldo: cpusldo {
				/* cpus */
				regulator-name = "axp2202-cpusldo";
				regulator-min-microvolt = <500000>;
				regulator-max-microvolt = <1400000>;
				regulator-boot-on;
				regulator-always-on;
			};
			reg_vmid: vmid {
				regulator-name = "axp2202-vmid";
				regulator-enable-ramp-delay = <1000>;
			};
			reg_drivevbus: drivevbus {
				regulator-name = "axp2202-drivevbus";
				regulator-enable-ramp-delay = <1000>;
				drivevbusin-supply = <&reg_vmid>;
			};
		};

		virtual-dcdc1 {
			compatible = "xpower-vregulator,dcdc1";
			dcdc1-supply = <&reg_dcdc1>;
		};
		virtual-dcdc2 {
			compatible = "xpower-vregulator,dcdc2";
			dcdc2-supply = <&reg_dcdc2>;
		};
		virtual-dcdc3 {
			compatible = "xpower-vregulator,dcdc3";
			dcdc3-supply = <&reg_dcdc3>;
		};
		virtual-dcdc4 {
			compatible = "xpower-vregulator,dcdc4";
			dcdc4-supply = <&reg_dcdc4>;
		};
		virtual-rtcldo {
			compatible = "xpower-vregulator,rtcldo";
			rtcldo-supply = <&reg_rtcldo>;
		};
		virtual-aldo1 {
			compatible = "xpower-vregulator,aldo1";
			aldo1-supply = <&reg_aldo1>;
		};
		virtual-aldo2 {
			compatible = "xpower-vregulator,aldo2";
			aldo2-supply = <&reg_aldo2>;
		};
		virtual-aldo3 {
			compatible = "xpower-vregulator,aldo3";
			aldo3-supply = <&reg_aldo3>;
		};
		virtual-aldo4 {
			compatible = "xpower-vregulator,aldo4";
			aldo4-supply = <&reg_aldo4>;
		};
		virtual-bldo1 {
			compatible = "xpower-vregulator,bldo1";
			bldo1-supply = <&reg_bldo1>;
		};
		virtual-bldo2 {
			compatible = "xpower-vregulator,bldo2";
			bldo2-supply = <&reg_bldo2>;
		};
		virtual-bldo3 {
			compatible = "xpower-vregulator,bldo3";
			bldo3-supply = <&reg_bldo3>;
		};
		virtual-bldo4 {
			compatible = "xpower-vregulator,bldo4";
			bldo4-supply = <&reg_bldo4>;
		};
		virtual-cldo1 {
			compatible = "xpower-vregulator,cldo1";
			cldo1-supply = <&reg_cldo1>;
		};
		virtual-cldo2 {
			compatible = "xpower-vregulator,cldo2";
			cldo2-supply = <&reg_cldo2>;
		};
		virtual-cldo3 {
			compatible = "xpower-vregulator,cldo3";
			cldo3-supply = <&reg_cldo3>;
		};
		virtual-cldo4 {
			compatible = "xpower-vregulator,cldo4";
			cldo4-supply = <&reg_cldo4>;
		};
		virtual-cpusldo {
			compatible = "xpower-vregulator,cpusldo";
			cpusldo-supply = <&reg_cpusldo>;
		};
		virtual-drivevbus {
			compatible = "xpower-vregulator,drivevbus";
			drivevbus-supply = <&reg_drivevbus>;
		};
		axp_gpio0: axp_gpio@0 {
			gpio-controller;
			#size-cells = <0>;
			#gpio-cells = <6>;
			status = "okay";
		};
	};
};

/{
	axp2202_parameter:axp2202-parameter {
		select = "battery-model";

		battery-model {
			parameter = /bits/ 8 <0x01 0xf5 0x00 0x00 0xfb 0x00 0x00 0xfb
				0x00 0x1e 0x32 0x02 0x14 0x05 0x0a 0x04
				0x74 0xfd 0xbc 0x0c 0xdf 0x10 0xcc 0xfb
				0x80 0x00 0xdc 0x18 0xe4 0x06 0xcc 0x06
				0x94 0x0b 0x4f 0x0f 0xcf 0x0f 0x6d 0x0a
				0x05 0x0e 0xcb 0x0e 0xc8 0x04 0xbb 0x04
				0xaa 0x09 0x98 0x0e 0x79 0x0e 0x67 0x09
				0x62 0x0e 0x08 0x0c 0x3e 0x02 0x0c 0x01
				0xda 0x06 0xa8 0x0b 0x71 0x0b 0x44 0x06
				0x12 0x72 0x3c 0x33 0x27 0x14 0x1a 0x0e>;
		};
	};
};

&nand0 {
	compatible = "allwinner,sun55iw3-nand";
	device_type = "nand0";
	//reg = <0x0 0x04011000 0x0 0x1000>;/* nand0 */
	pinctrl-names = "default", "sleep";
	pinctrl-0 = <&nand0_pins_default &nand0_pins_rb>;
	pinctrl-1 = <&nand0_pins_sleep>;
	nand0_regulator1 = "vcc-nand";
	nand0_regulator2 = "none";
	nand0_cache_level = <0x55aaaa55>;
	nand0_flush_cache_num = <0x55aaaa55>;
	nand0_capacity_level = <0x55aaaa55>;
	nand0_id_number_ctl = <0x55aaaa55>;
	nand0_print_level = <0x55aaaa55>;
	nand0_p0 = <0x55aaaa55>;
	nand0_p1 = <0x55aaaa55>;
	nand0_p2 = <0x55aaaa55>;
	nand0_p3 = <0x55aaaa55>;
	chip_code = "sun55iw3";
	status = "disabled";
};

&sdc2 {
	non-removable;
	bus-width = <8>;
	mmc-ddr-1_8v;
	mmc-hs200-1_8v;
	mmc-hs400-1_8v;
	no-sdio;
	no-sd;
	ctl-spec-caps = <0x328>;
	cap-mmc-highspeed;
	sunxi-power-save-mode;
	sunxi-dis-signal-vol-sw;
	mmc-bootpart-noacc;
	/*cap-hsq;*/
	cqe-on;
	ctl-cmdq-md = <0x2>;
	max-frequency = <200000000>;
	vmmc-supply = <&reg_cldo3>;
	/*emmc io vol 3.3v*/
	/*vqmmc-supply = <&reg_aldo1>;*/
	/*emmc io vol 1.8v*/
	vqmmc-supply = <&reg_cldo1>;
	status = "disabled";
};

&sdc0 {
	bus-width = <4>;
	cd-gpios = <&pio PF 6 (GPIO_ACTIVE_LOW | GPIO_PULL_UP)>;
	/*non-removable;*/
	/*broken-cd;*/
	/*cd-inverted*/
	/*data3-detect;*/
	/*card-pwr-gpios = <&pio PH 14 1 1 2 0xffffffff>;*/
	cd-used-24M;
	cd-set-debounce = <0x1>;
	cap-sd-highspeed;
	sd-uhs-sdr50;
	sd-uhs-ddr50;
	sd-uhs-sdr104;
	no-sdio;
	no-mmc;
	sunxi-power-save-mode;
	/*sunxi-dis-signal-vol-sw;*/
	max-frequency = <150000000>;
	ctl-spec-caps = <0x428>;
	vmmc-supply = <&reg_cldo3>;
	vqmmc33sw-supply = <&reg_cldo3>;
	vdmmc33sw-supply = <&reg_cldo3>;
	vqmmc18sw-supply = <&reg_cldo1>;
	vdmmc18sw-supply = <&reg_cldo1>;
	status = "okay";
};


&sdc1 {
	bus-width = <4>;
	no-mmc;
	no-sd;
	cap-sd-highspeed;
	/*sd-uhs-sdr12*/
	sd-uhs-sdr25;
	sd-uhs-sdr50;
	sd-uhs-ddr50;
	sd-uhs-sdr104;
	/*sunxi-power-save-mode;*/
	sunxi-dis-signal-vol-sw;
	cap-sdio-irq;
	keep-power-in-suspend;
	ignore-pm-notify;
	max-frequency = <208000000>;
	ctl-spec-caps = <0x428>;
	status = "okay";
};

&rfkill {
	compatible = "allwinner,sunxi-rfkill";
	chip_en  = <&r_pio PM 5 GPIO_ACTIVE_HIGH>;
	power_en = <&r_pio PL 7 GPIO_ACTIVE_HIGH>;
	pinctrl-0;
	pinctrl-names;
	status = "okay";

	/* wlan session */
	wlan {
		compatible    = "allwinner,sunxi-wlan";
		clocks        = <&rtc_ccu CLK_OSC32K_OUT>;
		clock-names   = "osc32k-out";
		wlan_power    = "axp2202-aldo3", "axp2202-bldo1", "axp2202-bldo2"; /* vcc-pl/vcc-pg/vcc-pm */
		wlan_power_vol= <3300000>, <1800000>, <1800000>;
		wlan_busnum   = <0x1>;
		wlan_regon    = <&r_pio PM 1 GPIO_ACTIVE_HIGH>;
		wlan_hostwake = <&r_pio PM 0 GPIO_ACTIVE_HIGH>;
		wakeup-source;
	};

	/* bt session */
	bt {
		compatible    = "allwinner,sunxi-bt";
		clocks        = <&rtc_ccu CLK_OSC32K_OUT>;
		clock-names   = "osc32k-out";
		bt_power    = "axp2202-aldo3", "axp2202-bldo1", "axp2202-bldo2"; /* vcc-pl/vcc-pg/vcc-pm */
		bt_power_vol= <3300000>, <1800000>, <1800000>;
		bt_rst_n      = <&r_pio PM 2 GPIO_ACTIVE_LOW>;
	};
};

&addr_mgt {
	compatible     = "allwinner,sunxi-addr_mgt";
	type_addr_wifi = <0x0>;
	type_addr_bt   = <0x0>;
	type_addr_eth  = <0x0>;
	status         = "okay";
};

&btlpm {
	compatible  = "allwinner,sunxi-btlpm";
	uart_index  = <0x1>;
	bt_wake     = <&r_pio PM 3 GPIO_ACTIVE_HIGH>;
	bt_hostwake = <&r_pio PM 4 GPIO_ACTIVE_HIGH>;
	wakeup-source;
	status      = "okay";
};

&usbc0 {
	usb-role-switch;
	port {
		#address-cells = <1>;
		#size-cells = <0>;
		usbc0_role_switch: endpoint@0 {
			reg = <0>;
			remote-endpoint = <&usbc0_role_sw>;
		};
	};
};

/*
 *usb_port_type: usb mode. 0-device, 1-host, 2-otg.
 *usb_detect_type: usb hotplug detect mode. 0-none, 1-vbus/id detect, 2-id/dpdm detect.
 *usb_detect_mode: 0-thread scan, 1-id gpio interrupt.
 *usb_id_gpio: gpio for id detect.
 *usb_det_vbus_gpio: gpio for id detect. gpio or "axp_ctrl";
 *usb_wakeup_suspend：0-SUPER_STANDBY, 1-USB_STANDBY.
 */
&usbc0 {
	device_type = "usbc0";
	usb_port_type = <0x2>;
	usb_detect_type = <0x3>;
	usb_detect_mode = <0x0>;
	usb_id_gpio;
	usb_det_vbus_gpio = "axp_ctrl";
	det_vbus_supply = <&usb_power_supply>;
	usb_regulator_io = "nocare";
	usb_wakeup_suspend = <1>;
	usb_luns = <3>;
	usb_serial_unique = <0>;
	usb_serial_number = "20080411";
	rndis_wceis = <1>;
	wakeup-source;
	status = "okay";
};

&udc {
	det_vbus_supply = <&usb_power_supply>;
	status = "okay";
};

&ehci0 {
	drvvbus-supply = <&reg_drivevbus>;
	status = "okay";
};

&ohci0 {
	drvvbus-supply = <&reg_drivevbus>;
	status = "okay";
};

&usbc1 {
	device_type = "usbc1";
	usb_regulator_io = "nocare";
	usb_wakeup_suspend = <1>;
	wakeup-source;
	status = "okay";
};

&ehci1 {
	drvvbus-supply = <&reg_usb1_vbus>;
	hci-supply = <&reg_vmid>;
	status = "okay";
};

&ohci1 {
	drvvbus-supply = <&reg_usb1_vbus>;
	hci-supply = <&reg_vmid>;
	status = "okay";
};

&usbc2 {
	device_type = "usbc2";
	drvvbus-supply = <&reg_usb2_vbus>;
	status = "okay";
};

&xhci2 {
	dr_mode = "host";
	status = "okay";
};

&u2phy {
	status = "okay";
};

&combophy {
	resets = <&ccu RST_BUS_PCIE_USB3>;
	phy_use_sel = <1>; /* 0:PCIE; 1:USB3 */
	status = "okay";
};

&gpu {
	gpu_idle = <1>;
	dvfs_status = <1>;
	mali-supply = <&reg_dcdc2>;
};

/*----------------------------------------------------------------------------------
disp init configuration

disp_mode             (0:screen0<screen0,fb0>)
screenx_output_type   (0:none; 1:lcd; 2:tv; 3:hdmi;5:vdpo)
screenx_output_mode   (used for hdmi output, 0:480i 1:576i 2:480p 3:576p 4:720p50)
                      (5:720p60 6:1080i50 7:1080i60 8:1080p24 9:1080p50 10:1080p60)
screenx_output_format (for hdmi, 0:RGB 1:yuv444 2:yuv422 3:yuv420)
screenx_output_bits   (for hdmi, 0:8bit 1:10bit 2:12bit 2:16bit)
screenx_output_eotf   (for hdmi, 0:reserve 4:SDR 16:HDR10 18:HLG)
screenx_output_cs     (for hdmi, 0:undefined  257:BT709 260:BT601  263:BT2020)
screenx_output_dvi_hdmi (for hdmi, 0:undefined 1:dvi mode 2:hdmi mode)
screen0_output_range   (for hdmi, 0:default 1:full 2:limited)
screen0_output_scan    (for hdmi, 0:no data 1:overscan 2:underscan)
screen0_output_aspect_ratio  (for hdmi, 8-same as original picture 9-4:3 10-16:9 11-14:9)
fbx format            (4:RGB655 5:RGB565 6:RGB556 7:ARGB1555 8:RGBA5551 9:RGB888 10:ARGB8888 12:ARGB4444)
fbx pixel sequence    (0:ARGB 1:BGRA 2:ABGR 3:RGBA)
fb0_scaler_mode_enable(scaler mode enable, used FE)
fbx_width,fbx_height  (framebuffer horizontal/vertical pixels, fix to output resolution while equal 0)
lcdx_backlight        (lcd init backlight,the range:[0,256],default:197
lcdx_yy               (lcd init screen bright/contrast/saturation/hue, value:0~100, default:50/50/57/50)
lcd0_contrast         (LCD contrast, 0~100)
lcd0_saturation       (LCD saturation, 0~100)
lcd0_hue              (LCD hue, 0~100)
framebuffer software rotation setting:
disp_rotation_used:   (0:disable; 1:enable,you must set fbX_width to lcd_y,
set fbX_height to lcd_x)
degreeX:              (X:screen index; 0:0 degree; 1:90 degree; 3:270 degree)
degreeX_Y:            (X:screen index; Y:layer index 0~15; 0:0 degree; 1:90 degree; 3:270 degree)
devX_output_type : config output type in bootGUI framework in UBOOT-2018.
				   (0:none; 1:lcd; 2:tv; 4:hdmi;)
devX_output_mode : config output resolution(see include/video/sunxi_display2.h) of bootGUI framework in UBOOT-2018
devX_screen_id   : config display index of bootGUI framework in UBOOT-2018
devX_do_hpd      : whether do hpd detectation or not in UBOOT-2018
chn_cfg_mode     : Hardware DE channel allocation config. 0:single display with 6
				   channel, 1:dual display with 4 channel in main display and 2 channel in second
                   display, 2:dual display with 3 channel in main display and 3 channel in second
                   in display.
----------------------------------------------------------------------------------*/

&disp {
	disp_init_enable         = <1>;
	disp_mode                = <0>;

	screen0_output_type      = <1>;
	screen0_output_mode      = <4>;
	screen0_to_lcd_index     = <1>;

	screen1_output_type      = <3>;
	screen1_output_mode      = <10>;

	screen1_output_format    = <0>;
	screen1_output_bits      = <0>;
	screen1_output_eotf      = <4>;
	screen1_output_cs        = <257>;
	screen1_output_dvi_hdmi  = <2>;
	screen1_output_range     = <2>;
	screen1_output_scan      = <0>;
	screen1_output_aspect_ratio = <8>;
	screen1_to_lcd_index     = <2>;

	dev0_output_type         = <1>;
	dev0_output_mode         = <4>;
	dev0_screen_id           = <0>;
	dev0_do_hpd              = <0>;

	dev1_output_type         = <4>;
	dev1_output_mode         = <10>;
	dev1_screen_id           = <1>;
	dev1_do_hpd              = <1>;

	def_output_dev           = <0>;
	hdmi_mode_check          = <1>;

	fb_format                = <0>;
	fb_num                   = <1>;
	fb_debug                 = <1>;
	/*<disp channel layer zorder>*/
	fb0_map                  = <0 1 0 16>;
	fb0_width                = <1920>;
	fb0_height               = <1080>;
	/*<disp channel layer zorder>*/
	fb1_map                  = <0 2 0 16>;
	fb1_width                = <300>;
	fb1_height               = <300>;
	/*<disp channel layer zorder>*/
	fb2_map                  = <1 0 0 16>;
	fb2_width                = <1280>;
	fb2_height               = <720>;
	/*<disp channel layer zorder>*/
	fb3_map                  = <1 1 0 16>;
	fb3_width                = <300>;
	fb3_height               = <300>;

	chn_cfg_mode             = <3>;
	disp_para_zone           = <1>;

	pwms = <&pwm0 7 5000000 0>;
	pwm-names = "backlight";
	/* VCC-LCD*/
	/* dc1sw-supply = <&reg_dc1sw>; */
	/* VCC-DSI */
	/* eldo3-supply = <&reg_eldo3>; */
	/* VCC-PD */
	/* dcdc1-supply = <&reg_dcdc1>; */

	cldo4-supply = <&reg_cldo4>;
	cldo1-supply = <&reg_cldo1>;

	pinctrl-names = "active", "sleep";
	pinctrl-0 = <&pwm0_0_pin_active>;
	pinctrl-1 = <&pwm0_0_pin_sleep>;
};

&lcd0 {
	lcd_used            = <1>;
	status              = "okay";
	lcd_driver_name     = "SQ101D_Q5DI404_84H501";
	lcd_backlight       = <50>;
	lcd_if              = <4>;

	lcd_x               = <1200>;
	lcd_y               = <1920>;
	lcd_width           = <136>;
	lcd_height          = <217>;
	lcd_dclk_freq       = <157>;

	lcd_pwm_used        = <0>;
	lcd_pwm_ch          = <7>;
	lcd_pwm_freq        = <50000>;
	lcd_pwm_pol         = <0>;
	lcd_pwm_max_limit   = <255>;

	lcd_hbp             = <50>;
	lcd_ht              = <1330>;
	lcd_hspw            = <10>;
	lcd_vbp             = <20>;
	lcd_vt              = <1960>;
	lcd_vspw            = <4>;

	lcd_frm             = <0>;
	lcd_gamma_en        = <0>;
	lcd_bright_curve_en = <0>;
	lcd_cmap_en         = <0>;

	deu_mode            = <0>;
	lcdgamma4iep        = <22>;
	smart_color         = <90>;

	lcd_dsi_if          = <0>;
	lcd_dsi_lane        = <4>;
	lcd_dsi_format      = <0>;
	lcd_dsi_te          = <0>;
	lcd_dsi_eotp        = <0>;

	lcd_power1 = "cldo4";
	lcd_power2 = "cldo1";

	lcd_gpio_2 = <&pio PD 22 GPIO_ACTIVE_HIGH>; //reset

	pinctrl-0 = <&dsi0_4lane_pins_a>;
	pinctrl-1 = <&dsi0_4lane_pins_b>;

	//lcd_bl_en = <&pio PH 18 GPIO_ACTIVE_HIGH>;
	lcd_bl_0_percent	= <5>;
	#if defined(SKTL_LCD_10)
	lcd_bl_100_percent  = <75>;
	#else
	lcd_bl_100_percent  = <90>;
	#endif
};

#if 0
&lcd1 {
	lcd_used            = <1>;
	status              = "okay";
	lcd_driver_name     = "SQ101D_Q5DI404_84H501";
	lcd_backlight       = <50>;
	lcd_if              = <4>;

	lcd_x               = <800>;
	lcd_y               = <1280>;
	lcd_width           = <136>;
	lcd_height          = <217>;
	lcd_dclk_freq       = <71>;

	lcd_pwm_used        = <1>;
	lcd_pwm_ch          = <0>;
	lcd_pwm_freq        = <50000>;
	lcd_pwm_pol         = <0>;
	lcd_pwm_max_limit   = <255>;

	lcd_hbp         = <56>;
	lcd_ht          = <908>;
	lcd_hspw        = <8>;
	lcd_vbp         = <21>;
	lcd_vt          = <1317>;
	lcd_vspw        = <6>;

	lcd_frm             = <0>;
	lcd_gamma_en        = <0>;
	lcd_bright_curve_en = <0>;
	lcd_cmap_en         = <0>;
	lcd_start_delay     = <2>;

	deu_mode            = <0>;
	lcdgamma4iep        = <22>;
	smart_color         = <90>;

	lcd_dsi_if          = <0>;
	lcd_dsi_lane        = <4>;
	lcd_dsi_format      = <0>;
	lcd_dsi_te          = <0>;
	lcd_dsi_eotp        = <0>;

	lcd_power1 = "cldo4";
	lcd_power2 = "cldo1";

	lcd_gpio_2 = <&pio PD 22 GPIO_ACTIVE_HIGH>; //reset

	pinctrl-0 = <&dsi1_4lane_pins_a>;
	pinctrl-1 = <&dsi1_4lane_pins_b>;

	lcd_bl_en = <&pio PH 18 GPIO_ACTIVE_HIGH>;
	lcd_bl_0_percent	= <5>;
	#if defined(SKTL_LCD_10)
	lcd_bl_100_percent  = <75>;
	#else
	lcd_bl_100_percent  = <90>;
	#endif
};
#else

&lcd1 {
	lcd_used            = <1>;

	lcd_driver_name     = "CC10132007_40A";
	lcd_backlight       = <50>;
	lcd_if              = <4>;

	lcd_x               = <800>;
	lcd_y               = <1280>;
	lcd_width           = <135>;
	lcd_height          = <216>;
	lcd_dclk_freq       = <68>;

	lcd_pwm_used        = <1>;
	lcd_pwm_ch          = <7>;
	lcd_pwm_freq        = <50000>;
	lcd_pwm_pol         = <0>;
	lcd_pwm_max_limit   = <255>;
	lcd_pwm_name        = "backlight";

	lcd_hbp             = <40>;
	lcd_ht              = <860>;
	lcd_hspw            = <20>;
	lcd_vbp             = <12>;
	lcd_vt              = <1322>;
	lcd_vspw            = <4>;

	lcd_frm             = <0>;
	lcd_gamma_en        = <0>;
	lcd_bright_curve_en = <0>;
	lcd_cmap_en         = <0>;
	lcd_start_delay     = <1>;

	lcd_dsi_if          = <0>;
	lcd_dsi_lane        = <4>;
	lcd_dsi_format      = <0>;
	lcd_dsi_te          = <0>;
	lcd_dsi_eotp        = <0>;

	deu_mode            = <0>;
	lcdgamma4iep        = <22>;
	smart_color         = <90>;

	lcd_power1 = "cldo4";
	lcd_power2 = "cldo1";

	lcd_gpio_2 = <&pio PD 22 GPIO_ACTIVE_HIGH>; //reset

	pinctrl-0 = <&dsi1_4lane_pins_a>;
	pinctrl-1 = <&dsi1_4lane_pins_b>;

	lcd_bl_en = <&pio PH 18 GPIO_ACTIVE_HIGH>;
	lcd_bl_0_percent	= <5>;

};
#endif

&lcd2 {
	lcd_used            = <1>;

	lcd_driver_name     = "default_lcd";
	lcd_backlight       = <50>;
	lcd_if              = <0>;

	lcd_x               = <800>;
	lcd_y               = <480>;
	lcd_width           = <150>;
	lcd_height          = <94>;
	lcd_dclk_freq       = <48>;

	lcd_pwm_used        = <1>;
	lcd_pwm_ch          = <7>;
	lcd_pwm_freq        = <50000>;
	lcd_pwm_pol         = <0>;

	lcd_hbp             = <55>;
	lcd_ht              = <1240>;
	lcd_hspw            = <20>;
	lcd_vbp             = <35>;
	lcd_vt              = <650>;
	lcd_vspw            = <10>;

	lcd_lvds_if         = <0>;
	lcd_lvds_colordepth = <1>;
	lcd_lvds_mode       = <0>;
	lcd_frm             = <1>;
	lcd_io_phase        = <0x0000>;
	lcd_gamma_en        = <0>;
	lcd_bright_curve_en = <0>;
	lcd_cmap_en         = <0>;

	deu_mode            = <0>;
	lcdgamma4iep        = <22>;
	smart_color         = <90>;

	pinctrl-0 = <&rgb24_pins_a>;
	pinctrl-1 = <&rgb24_pins_b>;
};

/*lvds*/
/*&lcd0 {
    lcd_used            = <1>;

    lcd_driver_name     = "default_lcd";
    lcd_backlight       = <50>;
    lcd_if              = <3>;
    lcd_x               = <1024>;
    lcd_y               = <600>;
    lcd_width           = <223>;
    lcd_height          = <125>;
    lcd_dclk_freq       = <51>;
    lcd_pwm_used        = <1>;
    lcd_pwm_ch          = <0>;
    lcd_pwm_freq        = <50000>;
    lcd_pwm_pol         = <0>;
    lcd_pwm_max_limit   = <255>;
    lcd_hbp             = <20>;
    lcd_ht              = <1344>;
    lcd_hspw            = <10>;
    lcd_vbp             = <20>;
    lcd_vt              = <635>;
    lcd_vspw            = <10>;
    lcd_lvds_if         = <0>;
    lcd_lvds_colordepth = <0>;
    lcd_lvds_mode       = <0>;
    lcd_frm             = <0>;
    lcd_hv_clk_phase    = <0>;
    lcd_hv_sync_polarity= <0>;
    lcd_gamma_en        = <0>;
    lcd_bright_curve_en = <0>;
    lcd_cmap_en         = <0>;

    deu_mode            = <0>;
    lcdgamma4iep        = <22>;
    smart_color         = <90>;
    pinctrl-0 = <&lvds0_pins_a>;
    pinctrl-1 = <&lvds0_pins_b>;
};*/

&edp0 {
	// use if hardware reset pin is need
	/* edp_hw_reset_pin = <&pio PH XX GPIO_ACTIVE_LOW>; */

	edp_ssc_en = <0>;
	edp_ssc_mode = <0>;
	edp_colordepth = <8>; /* 6/8/10/12/16 */
	edp_color_fmt = <0>; /* 0:RGB  1: YUV444  2: YUV422 */

	lane0_sw = <0>;
	lane0_pre = <0>;
	lane1_sw = <0>;
	lane1_pre = <0>;
	lane2_sw = <0>;
	lane2_pre = <0>;
	lane3_sw = <0>;
	lane3_pre = <0>;
	efficient_training = <0>;

	timings_fixed = <1>;
	edid_timings_prefer = <1>;
	sink_capacity_prefer = <1>;

	edp_panel_used = <1>;
	edp_panel_driver = "general_panel";
	edp_bl_en = <&pio PH 18 GPIO_ACTIVE_HIGH>;
	edp_pwm_used = <1>;
	edp_pwm_ch = <0>;
	edp_pwm_freq = <50000>;
	edp_pwm_pol = <0>;
	edp_default_backlight = <100>;
	edp_panel_power_0 = "edp-panel";
	edp_bl_power = "edp-backlight";

	vcc-edp-supply = <&reg_cldo1>;
	vdd-edp-supply = <&reg_dcdc2>;
	edp-panel-supply = <&reg_cldo4>;
	edp-backlight-supply = <&reg_bl_power>;
	status = "okay";
};

&hdmi {
	hdmi_used = <1>;
	cldo1-supply = <&reg_cldo1>;
	hdmi_power0 = "cldo1";
	vmid-supply = <&reg_vmid>;
	hdmi_power1 = "vmid";
	hdmi_power_cnt = <2>;
	hdmi_hdcp_enable = <1>;
	hdmi_hdcp22_enable = <0>;
	hdmi_cts_compatibility = <0>;
	hdmi_cec_support = <1>;
	hdmi_cec_super_standby = <1>;
	hdmi_skip_bootedid = <1>;

	ddc_en_io_ctrl = <0>;
	power_io_ctrl = <0>;

	status = "okay";
};

&cpu0 {
	cpu-supply = <&reg_dcdc1>;
};

&cpu4 {
	cpu-supply = <&reg_tcs0>;
};

&dsufreq {
	dsu-supply = <&reg_dcdc1>;
};

&ve {
	ve-supply = <&reg_dcdc2>;
};

/* audio dirver module -> audio codec */
&codec {
	tx-hub-en;
	rx-sync-en;

	dac-vol		= <63>;		/* default value:63 range:0->63 */
	dacl-vol	= <160>;	/* default value:160 range:0->255 */
	dacr-vol	= <160>;	/* default value:160 range:0->255 */
	adc1-vol	= <160>;	/* default value:160 range:0->255 */
	adc2-vol	= <160>;	/* default value:160 range:0->255 */
	adc3-vol	= <160>;	/* default value:160 range:0->255 */
	lineout-gain	= <31>;		/* default value:31 range:0->31 */
	hpout-gain	= <7>;		/* default value:7 range:0->7 */
	adc1-gain	= <31>;		/* default value:31 range:0->31 */
	adc2-gain	= <31>;		/* default value:31 range:0->31 */
	adc3-gain	= <31>;		/* default value:31 range:0->31 */

	/* to do: avcc-1.8 vdd33-3.3 cpvin-1.8 */
	avcc-external;
	avcc-supply	= <&reg_aldo4>;
	avcc-vol	= <1800000>;
	vdd-external;
	vdd-supply	= <&reg_cldo3>;
	vdd-vol		= <3300000>;
	cpvin-external;
	cpvin-supply	= <&reg_cldo1>;
	cpvin-vol	= <1800000>;

	pa-pin-max	= <1>;
	pa-pin-0	= <&pio PH 6 GPIO_ACTIVE_HIGH>;
	pa-pin-level-0	= <1>;
	pa-pin-msleep-0	= <0>;

	jack-det-level		= <0>;
	jack-det-threshold	= <8>;
	jack-det-debouce	= <0>; /* optional value range:0->15 */

	status = "okay";
};

&codec_plat {
	status = "okay";
};

&codec_mach {
	soundcard-mach,jack-support = <1>;
	status = "okay";
	soundcard-mach,cpu {
		sound-dai = <&codec_plat>;
	};
	soundcard-mach,codec {
		sound-dai = <&codec>;
	};
};

&hdmi_codec {
	status = "okay";
};

/* audio dirver module -> owa */
&owa_plat {
	pinctrl-used;
	pinctrl-names	= "default","sleep";
	pinctrl-0	= <&owa_pins_a>;
	pinctrl-1	= <&owa_pins_b>;
	tx-hub-en;
	status		= "okay";
};

&owa_mach {
	status		= "okay";
	soundcard-mach,cpu {
		sound-dai = <&owa_plat>;
	};
	soundcard-mach,codec {
	};
};

/* audio dirver module -> DMIC */
&dmic_plat {
	rx-chmap	= <0x76543210>;
	data-vol	= <0xB0>;
	rxdelaytime	= <0>;
	/* pinctrl-used; */
	/* pinctrl-names	= "default","sleep"; */
	/* pinctrl-0	= <&dmic_pins_a>; */
	/* pinctrl-1	= <&dmic_pins_b>; */
	rx-sync-en;
	status		= "disabled";
};

&dmic_mach {
	status		= "disabled";
	soundcard-mach,cpu {
		sound-dai = <&dmic_plat>;
	};
	soundcard-mach,codec {
	};
};

/* audio dirver module -> I2S/PCM */
&i2s0_plat {
	tdm-num		= <0>;
	tx-pin		= <0>;
	tx-pin0-map0	= <0x76543210>;
	tx-pin0-map1	= <0xFEDCBA98>;
	rx-pin		= <0>;
	pinctrl-used;
	pinctrl-names	= "default","sleep";
	pinctrl-0	= <&i2s0_pins_a &i2s0_pins_c &i2s0_pins_d>;
	pinctrl-1	= <&i2s0_pins_b>;
	tx-hub-en;
	rx-sync-en;
	status		= "okay";
};

&i2s0_mach {
	soundcard-mach,format		= "i2s";
	soundcard-mach,frame-master	= <&i2s0_cpu>;
	soundcard-mach,bitclock-master	= <&i2s0_cpu>;
	/* soundcard-mach,frame-inversion; */
	/* soundcard-mach,bitclock-inversion; */
	soundcard-mach,slot-num		= <2>;
	soundcard-mach,slot-width	= <32>;
	soundcard-mach,capture-only;
	status		= "okay";
	i2s0_cpu: soundcard-mach,cpu {
		sound-dai = <&i2s0_plat>;
		/* note: pll freq = 24.576M or 22.5792M * pll-fs */
		soundcard-mach,pll-fs	= <1>;
		/* note:
		 * mclk freq = mclk-fs * 12.288M or 11.2896M	(when mclk-fp ture)
		 * mclk freq = mclk-fs * pcm rate		(when mclk-fp false)
		 */
		soundcard-mach,mclk-fp;
		soundcard-mach,mclk-fs	= <1>;
	};
	i2s0_codec: soundcard-mach,codec {
		sound-dai               = <&ac107>;
		soundcard-mach,pll-fs   = <1>;
	};
};

&i2s1_plat {
	tdm-num		= <1>;
	tx-pin		= <0>;
	tx-pin0-map0	= <0x76543210>;
	tx-pin0-map1	= <0xFEDCBA98>;
	rx-pin		= <0>;
	pinctrl-used;
	pinctrl-names= "default","sleep";
	pinctrl-0	= <&i2s1_pins_a &i2s1_pins_c &i2s1_pins_d>;
	pinctrl-1	= <&i2s1_pins_b>;
	tx-hub-en;
	rx-sync-en;
	status		= "okay";
};

&i2s1_mach {
	soundcard-mach,format		= "dsp_a";
	soundcard-mach,frame-master	= <&i2s1_cpu>;
	soundcard-mach,bitclock-master	= <&i2s1_cpu>;
	/* soundcard-mach,frame-inversion; */
	soundcard-mach,bitclock-inversion;
	soundcard-mach,slot-num		= <2>;
	soundcard-mach,slot-width	= <32>;
	status		= "okay";
	i2s1_cpu: soundcard-mach,cpu {
		sound-dai = <&i2s1_plat>;
		soundcard-mach,pll-fs	= <1>;
		soundcard-mach,mclk-fs	= <0>;
	};
	i2s1_codec: soundcard-mach,codec {
	};
};

&i2s2_plat {
	tdm-num		= <2>;
	tx-pin		= <0 1 2 3>;
/* e.g.
 * tx-pin0-map0 = <0xFEDC3210> -> tx_pin_map[0][0] (Dout0-slot[7:0]  map channel[15:12, 3:0])
 * tx-pin0-map1 = <0x3210FEDC> -> tx_pin_map[0][1] (Dout0-slot[15:8] map channel[3:0, 15:12])
 * tx-pin1-map0 = <0x76543210> -> tx_pin_map[1][0] (Dout1-slot[7:0]  map channel[7:0])
 */
	tx-pin0-map0	= <0x76543210>;
	tx-pin0-map1	= <0xFEDCBA98>;
	tx-pin1-map0	= <0x76543210>;
	tx-pin1-map1	= <0xFEDCBA98>;
	tx-pin2-map0	= <0x76543210>;
	tx-pin2-map1	= <0xFEDCBA98>;
	tx-pin3-map0	= <0x76543210>;
	tx-pin3-map1	= <0xFEDCBA98>;
	rx-pin		= <0>;
	/* pinctrl-used; */
	/* pinctrl-names= "default","sleep"; */
	/* pinctrl-0	= <&i2s2_pins_a>; */
	/* pinctrl-1	= <&i2s2_pins_b>; */
	tx-hub-en;
	rx-sync-en;
	dai-type = "hdmi";
	status		= "okay";
};

&i2s2_mach {
	soundcard-mach,format		= "i2s";
	soundcard-mach,frame-master	= <&i2s2_cpu>;
	soundcard-mach,bitclock-master	= <&i2s2_cpu>;
	/* soundcard-mach,frame-inversion; */
	/* soundcard-mach,bitclock-inversion; */
	soundcard-mach,slot-num		= <2>;
	soundcard-mach,slot-width	= <32>;
	soundcard-mach,playback-only;
	status		= "okay";
	i2s2_cpu: soundcard-mach,cpu {
		sound-dai = <&i2s2_plat>;
		soundcard-mach,pll-fs	= <1>;
		soundcard-mach,mclk-fs	= <0>;
	};
	i2s2_codec: soundcard-mach,codec {
		sound-dai               = <&hdmi_codec>;
	};
};

&i2s3_plat {
	tdm-num		= <3>;
	tx-pin		= <0>;
	tx-pin0-map0	= <0x76543210>;
	tx-pin0-map1	= <0xFEDCBA98>;
	rx-pin		= <3>;
	rx-pin3-map0    = <0x33323130>;
	rx-pin3-map1    = <0x37363534>;
	rx-pin3-map2    = <0x3B3A3938>;
	rx-pin3-map3    = <0x3F3E3D3C>;
	pinctrl-used;
	pinctrl-names= "default","sleep";
	pinctrl-0	= <&i2s3_pins_a &i2s3_pins_c>;
	pinctrl-1	= <&i2s3_pins_b>;
	tx-hub-en;
	rx-sync-en;
	status		= "okay";
};

&i2s3_mach {
	soundcard-mach,format		= "i2s";
	soundcard-mach,frame-master	= <&i2s3_codec>;
	soundcard-mach,bitclock-master	= <&i2s3_codec>;
	/* soundcard-mach,frame-inversion; */
	/* soundcard-mach,bitclock-inversion; */
	soundcard-mach,slot-num		= <2>;
	soundcard-mach,slot-width	= <32>;
	soundcard-mach,wait-time        = <4000>;
	status		= "okay";
	i2s3_cpu: soundcard-mach,cpu {
		sound-dai = <&i2s3_plat>;
		soundcard-mach,pll-fs	= <1>;
		soundcard-mach,mclk-fs	= <0>;
	};
	i2s3_codec: soundcard-mach,codec {
	};
};

&vind0 {
	csi_top = <384000000>;
	csi_isp = <312000000>;
	vind_mclkpin-supply = <&reg_aldo2>;
	vind_mclkpin_vol = <1800000>;
	vind_mcsipin-supply = <&reg_cldo1>;
	vind_mcsipin_vol = <1800000>;
	vind_mipipin-supply = <&reg_cldo3>;
	vind_mipipin_vol = <3300000>;
	status = "okay";

	csi3:csi@5823000 {
		pinctrl-names = "default","sleep";
		pinctrl-0 = <&ncsi_pins_a>;
		pinctrl-1 = <&ncsi_pins_b>;
		status = "disabled";
	};

	tdm0:tdm@5908000 {
		work_mode = <0>;
	};

	isp00:isp@5900000 {
		work_mode = <0>;
	};

	isp01:isp@58ffffc {
		status = "disabled";
	};

	isp02:isp@58ffff8 {
		status = "disabled";
	};

	isp03:isp@58ffff4 {
		status = "disabled";
	};

	isp10:isp@4 {
		status = "okay";
	};

	scaler00:scaler@5910000 {
		work_mode = <0>;
	};

	scaler01:scaler@590fffc {
		status = "disabled";
	};

	scaler02:scaler@590fff8 {
		status = "disabled";
	};

	scaler03:scaler@590fff4 {
		status = "disabled";
	};

	scaler10:scaler@5910400 {
		work_mode = <0>;
	};

	scaler11:scaler@59103fc {
		status = "disabled";
	};

	scaler12:scaler@59103f8 {
		status = "disabled";
	};

	scaler13:scaler@59103f4 {
		status = "disabled";
	};

	scaler20:scaler@5910800 {
		work_mode = <0>;
	};

	scaler21:scaler@59107fc {
		status = "disabled";
	};

	scaler22:scaler@59107f8 {
		status = "disabled";
	};

	scaler23:scaler@59107f4 {
		status = "disabled";
	};

	scaler30:scaler@5910c00 {
		work_mode = <0>;
	};

	scaler31:scaler@5910bfc {
		status = "disabled";
	};

	scaler32:scaler@5910bf8 {
		status = "disabled";
	};

	scaler33:scaler@5910bf4 {
		status = "disabled";
	};

	actuator0: actuator@2108180 {
		device_type = "actuator0";
		actuator0_name = "dw9714_act";
		actuator0_slave = <0x18>;
		actuator0_af_pwdn = <>;
		actuator0_afvdd = "afvcc-csi";
		actuator0_afvdd_vol = <3300000>;
		status = "disabled";
	};

	flash0: flash@2108190 {
		device_type = "flash0";
		flash0_type = <2>;
		flash0_en = <&r_pio PL 11 GPIO_ACTIVE_LOW>;
		flash0_mode = <>;
		flash0_flvdd = "";
		flash0_flvdd_vol = <>;
		device_id = <0>;
		status = "disabled";
	};

	sensor_detect: sensor_detect@2108200 {
		hotplug_gpios = <&pio PI 12 GPIO_ACTIVE_LOW>;
		power_gpios = <&r_pio PL 5 GPIO_ACTIVE_LOW>;
		reset_gpios = <&pio PI 7 GPIO_ACTIVE_LOW>;
		usbsw_gpios = <&r_pio PL 12 GPIO_ACTIVE_LOW>;
	};

	sensor0:sensor@5812000 {
		device_type = "sensor0";
		sensor0_mname = "lt7911d_mipi";
		sensor0_twi_cci_id = <5>;
		sensor0_twi_addr = <0x56>;
		sensor0_mclk_id = <2>;
		sensor0_pos = "rear";
		sensor0_isp_used = <0>;
		sensor0_fmt = <0>;
		sensor0_stby_mode = <0>;
		sensor0_vflip = <0>;
		sensor0_hflip = <0>;
		sensor0_cameravdd-supply = <>;
		sensor0_cameravdd_vol = <2800000>;
		sensor0_iovdd-supply = <>;
		sensor0_iovdd_vol = <1800000>;
		sensor0_avdd-supply = <>;
		sensor0_avdd_vol = <2800000>;
		sensor0_dvdd-supply = <>;
		sensor0_dvdd_vol = <1500000>;
		sensor0_power_en = <>;
		sensor0_reset = <>;
		sensor0_pwdn = <>;
		status = "okay";
	};

	sensor1:sensor@5812010 {
		device_type = "sensor1";
		sensor1_mname = "gc02m2_mipi";
		sensor1_twi_cci_id = <4>;
		sensor1_twi_addr = <0x6e>;
		sensor1_mclk_id = <2>;
		sensor1_pos = "front";
		sensor1_isp_used = <1>;
		sensor1_fmt = <1>;
		sensor1_stby_mode = <0>;
		sensor1_vflip = <0>;
		sensor1_hflip = <0>;
		sensor1_iovdd-supply = <&reg_aldo2>;
		sensor1_iovdd_vol = <1800000>;
		sensor1_avdd-supply = <&reg_aldo1>;
		sensor1_avdd_vol = <2800000>;
		sensor1_dvdd-supply = <&reg_bldo4>;
		sensor1_dvdd_vol = <1800000>;
		sensor1_power_en = <>;
		sensor1_reset = <&pio PE 7 GPIO_ACTIVE_LOW>;
		sensor1_pwdn = <&pio PE 6 GPIO_ACTIVE_LOW>;
		status = "disabled";
	};

	vinc00:vinc@5830000 {
		vinc0_csi_sel = <0>;
		vinc0_mipi_sel = <0>;
		vinc0_isp_sel = <4>;
		vinc0_isp_tx_ch = <0>;
		vinc0_tdm_rx_sel = <0>;
		vinc0_rear_sensor_sel = <0>;
		vinc0_front_sensor_sel = <0>;
		vinc0_sensor_list = <0>;
		device_id = <0>;
		work_mode = <0x0>;
		status = "okay";
	};

	vinc01:vinc@582fffc {
		vinc1_csi_sel = <1>;
		vinc1_mipi_sel = <2>;
		vinc1_isp_sel = <1>;
		vinc1_isp_tx_ch = <0>;
		vinc1_tdm_rx_sel = <1>;
		vinc1_rear_sensor_sel = <1>;
		vinc1_front_sensor_sel = <1>;
		vinc1_sensor_list = <0>;
		device_id = <1>;
		status = "disabled";
	};

	vinc02:vinc@582fff8 {
		vinc2_csi_sel = <2>;
		vinc2_mipi_sel = <0xff>;
		vinc2_isp_sel = <2>;
		vinc2_isp_tx_ch = <2>;
		vinc2_tdm_rx_sel = <2>;
		vinc2_rear_sensor_sel = <0>;
		vinc2_front_sensor_sel = <0>;
		vinc2_sensor_list = <0>;
		device_id = <2>;
		status = "disabled";
	};

	vinc03:vinc@582fff4 {
		vinc3_csi_sel = <0>;
		vinc3_mipi_sel = <0xff>;
		vinc3_isp_sel = <0>;
		vinc3_isp_tx_ch = <0>;
		vinc3_tdm_rx_sel = <0>;
		vinc3_rear_sensor_sel = <1>;
		vinc3_front_sensor_sel = <1>;
		vinc3_sensor_list = <0>;
		device_id = <3>;
		status = "disabled";
	};

	vinc10:vinc@5831000 {
		vinc4_csi_sel = <0>;
		vinc4_mipi_sel = <0>;
		vinc4_isp_sel = <4>;
		vinc4_isp_tx_ch = <0>;
		vinc4_tdm_rx_sel = <0>;
		vinc4_rear_sensor_sel = <0>;
		vinc4_front_sensor_sel = <0>;
		vinc4_sensor_list = <0>;
		device_id = <4>;
		work_mode = <0x0>;
		status = "okay";
	};

	vinc11:vinc@5830ffc {
		vinc5_csi_sel = <2>;
		vinc5_mipi_sel = <0xff>;
		vinc5_isp_sel = <1>;
		vinc5_isp_tx_ch = <1>;
		vinc5_tdm_rx_sel = <1>;
		vinc5_rear_sensor_sel = <0>;
		vinc5_front_sensor_sel = <0>;
		vinc5_sensor_list = <0>;
		device_id = <5>;
		status = "disabled";
	};

	vinc12:vinc@5830ff8 {
		vinc6_csi_sel = <2>;
		vinc6_mipi_sel = <0xff>;
		vinc6_isp_sel = <0>;
		vinc6_isp_tx_ch = <0>;
		vinc6_tdm_rx_sel = <0>;
		vinc6_rear_sensor_sel = <0>;
		vinc6_front_sensor_sel = <0>;
		vinc6_sensor_list = <0>;
		device_id = <6>;
		status = "disabled";
	};

	vinc13:vinc@5830ff4 {
		vinc7_csi_sel = <2>;
		vinc7_mipi_sel = <0xff>;
		vinc7_isp_sel = <0>;
		vinc7_isp_tx_ch = <0>;
		vinc7_tdm_rx_sel = <0>;
		vinc7_rear_sensor_sel = <0>;
		vinc7_front_sensor_sel = <0>;
		vinc7_sensor_list = <0>;
		device_id = <7>;
		status = "disabled";
	};

	vinc20:vinc@5832000 {
		vinc8_csi_sel = <2>;
		vinc8_mipi_sel = <2>;
		vinc8_isp_sel = <0>;
		vinc8_isp_tx_ch = <0>;
		vinc8_tdm_rx_sel = <0>;
		vinc8_rear_sensor_sel = <1>;
		vinc8_front_sensor_sel = <1>;
		vinc8_sensor_list = <0>;
		device_id = <8>;
		work_mode = <0x0>;
		status = "disabled";
	};

	vinc21:vinc@5831ffc {
		vinc9_csi_sel = <2>;
		vinc9_mipi_sel = <0xff>;
		vinc9_isp_sel = <0>;
		vinc9_isp_tx_ch = <0>;
		vinc9_tdm_rx_sel = <0>;
		vinc9_rear_sensor_sel = <0>;
		vinc9_front_sensor_sel = <0>;
		vinc9_sensor_list = <0>;
		device_id = <9>;
		status = "disabled";
	};

	vinc22:vinc@5831ff8 {
		vinc10_csi_sel = <2>;
		vinc10_mipi_sel = <0xff>;
		vinc10_isp_sel = <0>;
		vinc10_isp_tx_ch = <0>;
		vinc10_tdm_rx_sel = <0>;
		vinc10_rear_sensor_sel = <0>;
		vinc10_front_sensor_sel = <0>;
		vinc10_sensor_list = <0>;
		device_id = <10>;
		status = "disabled";
	};

	vinc23:vinc@5831ff4 {
		vinc11_csi_sel = <2>;
		vinc11_mipi_sel = <0xff>;
		vinc11_isp_sel = <0>;
		vinc11_isp_tx_ch = <0>;
		vinc11_tdm_rx_sel = <0>;
		vinc11_rear_sensor_sel = <0>;
		vinc11_front_sensor_sel = <0>;
		vinc11_sensor_list = <0>;
		device_id = <11>;
		status = "disabled";
	};

	vinc30:vinc@5833000 {
		vinc12_csi_sel = <2>;
		vinc12_mipi_sel = <2>;
		vinc12_isp_sel = <0>;
		vinc12_isp_tx_ch = <0>;
		vinc12_tdm_rx_sel = <0>;
		vinc12_rear_sensor_sel = <1>;
		vinc12_front_sensor_sel = <1>;
		vinc12_sensor_list = <0>;
		device_id = <12>;
		work_mode = <0x0>;
		status = "disabled";
	};

	vinc31:vinc@5832ffc {
		vinc13_csi_sel = <2>;
		vinc13_mipi_sel = <0xff>;
		vinc13_isp_sel = <0>;
		vinc13_isp_tx_ch = <0>;
		vinc13_tdm_rx_sel = <0>;
		vinc13_rear_sensor_sel = <0>;
		vinc13_front_sensor_sel = <0>;
		vinc13_sensor_list = <0>;
		device_id = <13>;
		status = "disabled";
	};

	vinc32:vinc@5832ff8 {
		vinc14_csi_sel = <2>;
		vinc14_mipi_sel = <0xff>;
		vinc14_isp_sel = <0>;
		vinc14_isp_tx_ch = <0>;
		vinc14_tdm_rx_sel = <0>;
		vinc14_rear_sensor_sel = <0>;
		vinc14_front_sensor_sel = <0>;
		vinc14_sensor_list = <0>;
		device_id = <14>;
		status = "disabled";
	};

	vinc33:vinc@5832ff4 {
		vinc15_csi_sel = <2>;
		vinc15_mipi_sel = <0xff>;
		vinc15_isp_sel = <0>;
		vinc15_isp_tx_ch = <0>;
		vinc15_tdm_rx_sel = <0>;
		vinc15_rear_sensor_sel = <0>;
		vinc15_front_sensor_sel = <0>;
		vinc15_sensor_list = <0>;
		device_id = <15>;
		status = "disabled";
	};

	vinc40:vinc@5834000 {
		vinc16_csi_sel = <2>;
		vinc16_mipi_sel = <0xff>;
		vinc16_isp_sel = <0>;
		vinc16_isp_tx_ch = <0>;
		vinc16_tdm_rx_sel = <0>;
		vinc16_rear_sensor_sel = <0>;
		vinc16_front_sensor_sel = <0>;
		vinc16_sensor_list = <0>;
		device_id = <16>;
		status = "disabled";
	};

	vinc50:vinc@5835000 {
		vinc17_csi_sel = <2>;
		vinc17_mipi_sel = <0xff>;
		vinc17_isp_sel = <0>;
		vinc17_isp_tx_ch = <0>;
		vinc17_tdm_rx_sel = <0>;
		vinc17_rear_sensor_sel = <0>;
		vinc17_front_sensor_sel = <0>;
		vinc17_sensor_list = <0>;
		device_id = <17>;
		status = "disabled";
	};
};
